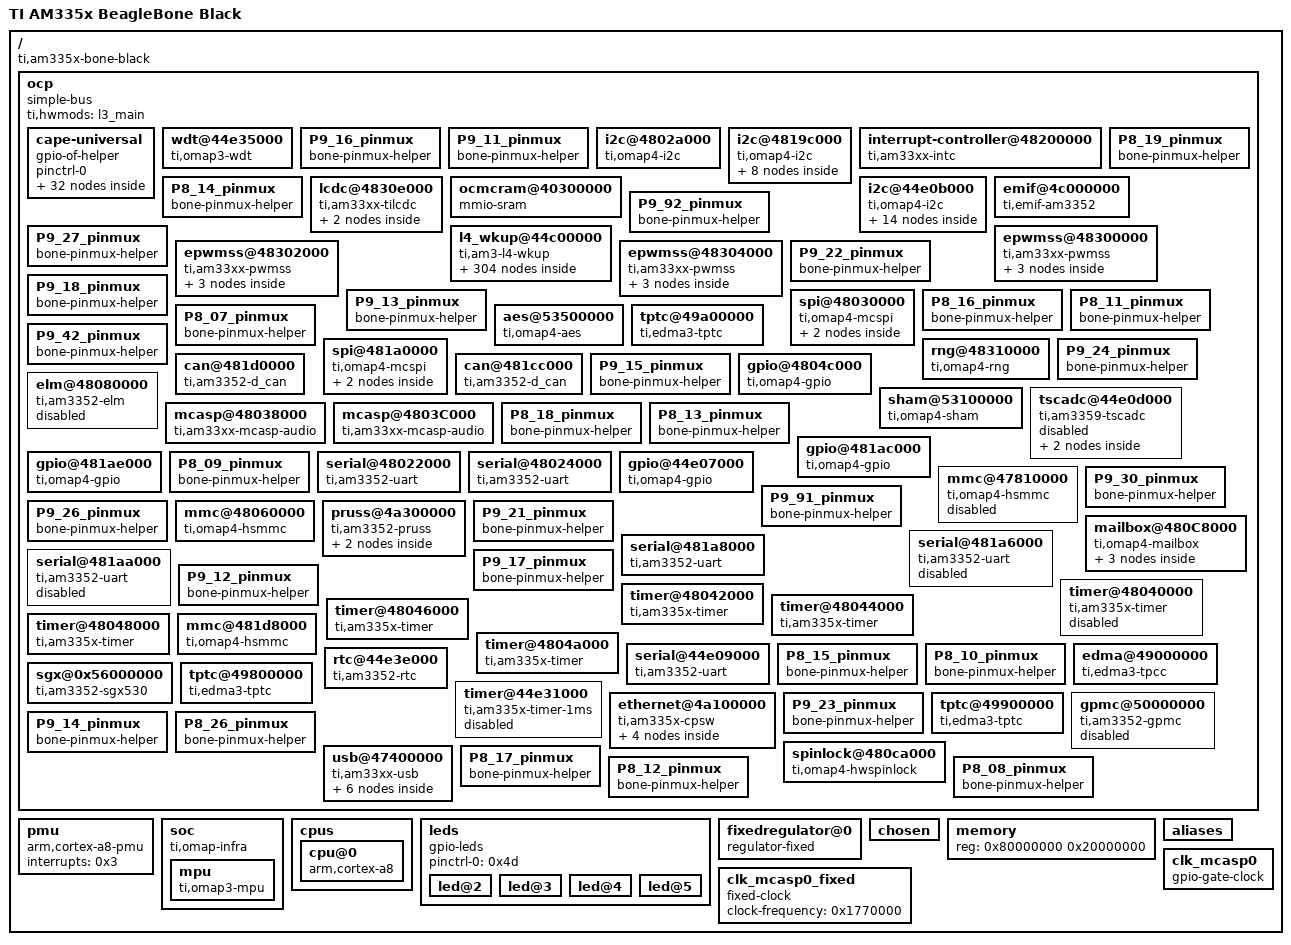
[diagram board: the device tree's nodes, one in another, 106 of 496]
/dts-v1/;

/ {
	model = "TI AM335x BeagleBone Black";
	compatible = "ti,am335x-bone-black", "ti,am335x-bone", "ti,am33xx";
	#address-cells = <0x1>;
	#size-cells = <0x1>;
	interrupt-parent = <0x1>;

	ocp {
		compatible = "simple-bus";
		ranges;
		#address-cells = <0x1>;
		ti,hwmods = "l3_main";
		phandle = <0x58>;
		#size-cells = <0x1>;
		linux,phandle = <0x58>;

		cape-universal {
			pinctrl-0;
			compatible = "gpio-of-helper";
			status = "okay";
			pinctrl-names = "default";

			P8_07 {
				gpio = <0x8f 0x2 0x0>;
				input;
				dir-changeable;
				gpio-name = "P8_07";
			};

			P8_08 {
				gpio = <0x8f 0x3 0x0>;
				input;
				dir-changeable;
				gpio-name = "P8_08";
			};

			P8_09 {
				gpio = <0x8f 0x5 0x0>;
				input;
				dir-changeable;
				gpio-name = "P8_09";
			};

			P8_10 {
				gpio = <0x8f 0x4 0x0>;
				input;
				dir-changeable;
				gpio-name = "P8_10";
			};

			P8_11 {
				gpio = <0x4e 0xd 0x0>;
				input;
				dir-changeable;
				gpio-name = "P8_11";
			};

			P8_12 {
				gpio = <0x4e 0xc 0x0>;
				input;
				dir-changeable;
				gpio-name = "P8_12";
			};

			P8_13 {
				gpio = <0x37 0x17 0x0>;
				input;
				dir-changeable;
				gpio-name = "P8_13";
			};

			P8_14 {
				gpio = <0x37 0x1a 0x0>;
				input;
				dir-changeable;
				gpio-name = "P8_14";
			};

			P8_15 {
				gpio = <0x4e 0xf 0x0>;
				input;
				dir-changeable;
				gpio-name = "P8_15";
			};

			P8_16 {
				gpio = <0x4e 0xe 0x0>;
				input;
				dir-changeable;
				gpio-name = "P8_16";
			};

			P8_17 {
				gpio = <0x37 0x1b 0x0>;
				input;
				dir-changeable;
				gpio-name = "P8_17";
			};

			P8_18 {
				gpio = <0x8f 0x1 0x0>;
				input;
				dir-changeable;
				gpio-name = "P8_18";
			};

			P8_19 {
				gpio = <0x37 0x16 0x0>;
				input;
				dir-changeable;
				gpio-name = "P8_19";
			};

			P8_26 {
				gpio = <0x4e 0x1d 0x0>;
				input;
				dir-changeable;
				gpio-name = "P8_26";
			};

			P9_11 {
				gpio = <0x37 0x1e 0x0>;
				input;
				dir-changeable;
				gpio-name = "P9_11";
			};

			P9_12 {
				gpio = <0x4e 0x1c 0x0>;
				input;
				dir-changeable;
				gpio-name = "P9_12";
			};

			P9_13 {
				gpio = <0x37 0x1f 0x0>;
				input;
				dir-changeable;
				gpio-name = "P9_13";
			};

			P9_14 {
				gpio = <0x4e 0x12 0x0>;
				input;
				dir-changeable;
				gpio-name = "P9_14";
			};

			P9_15 {
				gpio = <0x4e 0x10 0x0>;
				input;
				dir-changeable;
				gpio-name = "P9_15";
			};

			P9_16 {
				gpio = <0x4e 0x13 0x0>;
				input;
				dir-changeable;
				gpio-name = "P9_16";
			};

			P9_17 {
				gpio = <0x37 0x5 0x0>;
				input;
				dir-changeable;
				gpio-name = "P9_17";
			};

			P9_18 {
				gpio = <0x37 0x4 0x0>;
				input;
				dir-changeable;
				gpio-name = "P9_18";
			};

			P9_21 {
				gpio = <0x37 0x3 0x0>;
				input;
				dir-changeable;
				gpio-name = "P9_21";
			};

			P9_22 {
				gpio = <0x37 0x2 0x0>;
				input;
				dir-changeable;
				gpio-name = "P9_22";
			};

			P9_23 {
				gpio = <0x4e 0x11 0x0>;
				input;
				dir-changeable;
				gpio-name = "P9_23";
			};

			P9_24 {
				gpio = <0x37 0xf 0x0>;
				input;
				dir-changeable;
				gpio-name = "P9_24";
			};

			P9_26 {
				gpio = <0x37 0xe 0x0>;
				input;
				dir-changeable;
				gpio-name = "P9_26";
			};

			P9_27 {
				gpio = <0x90 0x13 0x0>;
				input;
				dir-changeable;
				gpio-name = "P9_27";
			};

			P9_30 {
				gpio = <0x90 0x10 0x0>;
				input;
				dir-changeable;
				gpio-name = "P9_30";
			};

			P9_42 {
				gpio = <0x37 0x7 0x0>;
				input;
				dir-changeable;
				gpio-name = "P9_42";
			};

			P9_91 {
				gpio = <0x90 0x14 0x0>;
				input;
				dir-changeable;
				gpio-name = "P9_91";
			};

			P9_92 {
				gpio = <0x90 0x12 0x0>;
				input;
				dir-changeable;
				gpio-name = "P9_92";
			};
		};

		wdt@44e35000 {
			reg = <0x44e35000 0x1000>;
			interrupts = <0x5b>;
			compatible = "ti,omap3-wdt";
			ti,hwmods = "wd_timer2";
			phandle = <0xaa>;
			linux,phandle = <0xaa>;
		};

		P9_16_pinmux {
			pinctrl-0 = <0x13a>;
			pinctrl-1 = <0x13b>;
			pinctrl-2 = <0x13c>;
			pinctrl-3 = <0x13d>;
			pinctrl-4 = <0x13e>;
			compatible = "bone-pinmux-helper";
			status = "okay";
			pinctrl-names = "default", "gpio", "gpio_pu", "gpio_pd", "pwm";
		};

		P9_11_pinmux {
			pinctrl-0 = <0x122>;
			pinctrl-1 = <0x123>;
			pinctrl-2 = <0x124>;
			pinctrl-3 = <0x125>;
			pinctrl-4 = <0x126>;
			compatible = "bone-pinmux-helper";
			status = "okay";
			pinctrl-names = "default", "gpio", "gpio_pu", "gpio_pd", "uart";
		};

		i2c@4802a000 {
			reg = <0x4802a000 0x1000>;
			interrupts = <0x47>;
			pinctrl-0;
			compatible = "ti,omap4-i2c";
			clock-frequency = <0x186a0>;
			status = "okay";
			#address-cells = <0x1>;
			ti,hwmods = "i2c2";
			phandle = <0xa0>;
			#size-cells = <0x0>;
			pinctrl-names = "default";
			linux,phandle = <0xa0>;
		};

		i2c@4819c000 {
			reg = <0x4819c000 0x1000>;
			interrupts = <0x1e>;
			pinctrl-0 = <0x33>;
			compatible = "ti,omap4-i2c";
			clock-frequency = <0x186a0>;
			status = "okay";
			#address-cells = <0x1>;
			ti,hwmods = "i2c3";
			phandle = <0xa1>;
			#size-cells = <0x0>;
			pinctrl-names = "default";
			linux,phandle = <0xa1>;

			cape_eeprom0@54 {
				reg = <0x54>;
				compatible = "at,24c256";
				#address-cells = <0x1>;
				phandle = <0xa2>;
				#size-cells = <0x1>;
				linux,phandle = <0xa2>;

				cape_data@0 {
					reg = <0x0 0x100>;
					phandle = <0x50>;
					linux,phandle = <0x50>;
				};
			};

			cape_eeprom1@55 {
				reg = <0x55>;
				compatible = "at,24c256";
				#address-cells = <0x1>;
				phandle = <0xa3>;
				#size-cells = <0x1>;
				linux,phandle = <0xa3>;

				cape_data@0 {
					reg = <0x0 0x100>;
					phandle = <0x51>;
					linux,phandle = <0x51>;
				};
			};

			cape_eeprom2@56 {
				reg = <0x56>;
				compatible = "at,24c256";
				#address-cells = <0x1>;
				phandle = <0xa4>;
				#size-cells = <0x1>;
				linux,phandle = <0xa4>;

				cape_data@0 {
					reg = <0x0 0x100>;
					phandle = <0x52>;
					linux,phandle = <0x52>;
				};
			};

			cape_eeprom3@57 {
				reg = <0x57>;
				compatible = "at,24c256";
				#address-cells = <0x1>;
				phandle = <0xa5>;
				#size-cells = <0x1>;
				linux,phandle = <0xa5>;

				cape_data@0 {
					reg = <0x0 0x100>;
					phandle = <0x53>;
					linux,phandle = <0x53>;
				};
			};
		};

		interrupt-controller@48200000 {
			reg = <0x48200000 0x1000>;
			compatible = "ti,am33xx-intc";
			#interrupt-cells = <0x1>;
			phandle = <0x1>;
			interrupt-controller;
			linux,phandle = <0x1>;
		};

		P8_19_pinmux {
			pinctrl-0 = <0x119>;
			pinctrl-1 = <0x11a>;
			pinctrl-2 = <0x11b>;
			pinctrl-3 = <0x11c>;
			pinctrl-4 = <0x11d>;
			compatible = "bone-pinmux-helper";
			status = "okay";
			pinctrl-names = "default", "gpio", "gpio_pu", "gpio_pd", "pwm";
		};

		P8_14_pinmux {
			pinctrl-0 = <0xff>;
			pinctrl-1 = <0x100>;
			pinctrl-2 = <0x101>;
			pinctrl-3 = <0x102>;
			pinctrl-4 = <0x103>;
			compatible = "bone-pinmux-helper";
			status = "okay";
			pinctrl-names = "default", "gpio", "gpio_pu", "gpio_pd", "pwm";
		};

		lcdc@4830e000 {
			reg = <0x4830e000 0x1000>;
			interrupts = <0x24>;
			compatible = "ti,am33xx-tilcdc";
			status = "okay";
			ti,hwmods = "lcdc";
			phandle = <0xce>;
			linux,phandle = <0xce>;
			interrupt-parent = <0x1>;

			port {

				endpoint@0 {
					remote-endpoint = <0x4a>;
					phandle = <0x32>;
					linux,phandle = <0x32>;
				};
			};
		};

		ocmcram@40300000 {
			reg = <0x40300000 0x10000>;
			compatible = "mmio-sram";
			map-exec;
			phandle = <0x4>;
			linux,phandle = <0x4>;
		};

		i2c@44e0b000 {
			reg = <0x44e0b000 0x1000>;
			interrupts = <0x46>;
			pinctrl-0 = <0x2f>;
			compatible = "ti,omap4-i2c";
			clock-frequency = <0x61a80>;
			status = "okay";
			#address-cells = <0x1>;
			ti,hwmods = "i2c1";
			phandle = <0x97>;
			#size-cells = <0x0>;
			pinctrl-names = "default";
			linux,phandle = <0x97>;

			baseboard_eeprom@50 {
				reg = <0x50>;
				compatible = "at,24c256";
				#address-cells = <0x1>;
				phandle = <0x9f>;
				#size-cells = <0x1>;
				linux,phandle = <0x9f>;

				baseboard_data@0 {
					reg = <0x0 0x100>;
					phandle = <0x4f>;
					linux,phandle = <0x4f>;
				};
			};

			tps@24 {
				reg = <0x24>;
				interrupts = <0x7>;
				compatible = "ti,tps65217";
				ti,pmic-shutdown-controller;
				phandle = <0x98>;
				linux,phandle = <0x98>;
				interrupt-parent = <0x1>;

				regulators {
					#address-cells = <0x1>;
					#size-cells = <0x0>;

					regulator@0 {
						reg = <0x0>;
						regulator-name = "vdds_dpr";
						regulator-always-on;
						regulator-compatible = "dcdc1";
						phandle = <0x99>;
						linux,phandle = <0x99>;
					};

					regulator@1 {
						reg = <0x1>;
						regulator-name = "vdd_mpu";
						regulator-always-on;
						regulator-min-microvolt = <0xe1d48>;
						regulator-max-microvolt = <0x1506d0>;
						regulator-compatible = "dcdc2";
						phandle = <0x3>;
						regulator-boot-on;
						linux,phandle = <0x3>;
					};

					regulator@2 {
						reg = <0x2>;
						regulator-name = "vdd_core";
						regulator-always-on;
						regulator-min-microvolt = <0xe1d48>;
						regulator-max-microvolt = <0x118c30>;
						regulator-compatible = "dcdc3";
						phandle = <0x9a>;
						regulator-boot-on;
						linux,phandle = <0x9a>;
					};

					regulator@3 {
						reg = <0x3>;
						regulator-name = "vio,vrtc,vdds";
						regulator-always-on;
						regulator-compatible = "ldo1";
						phandle = <0x9b>;
						linux,phandle = <0x9b>;
					};

					regulator@4 {
						reg = <0x4>;
						regulator-name = "vdd_3v3aux";
						regulator-always-on;
						regulator-compatible = "ldo2";
						phandle = <0x9c>;
						linux,phandle = <0x9c>;
					};

					regulator@5 {
						reg = <0x5>;
						regulator-name = "vdd_1v8";
						regulator-always-on;
						regulator-min-microvolt = <0x1b7740>;
						regulator-max-microvolt = <0x1b7740>;
						regulator-compatible = "ldo3";
						phandle = <0x9d>;
						linux,phandle = <0x9d>;
					};

					regulator@6 {
						reg = <0x6>;
						regulator-name = "vdd_3v3a";
						regulator-always-on;
						regulator-compatible = "ldo4";
						phandle = <0x9e>;
						linux,phandle = <0x9e>;
					};
				};
			};

			tda19988 {
				reg = <0x70>;
				pinctrl-0 = <0x30>;
				pinctrl-1 = <0x31>;
				compatible = "nxp,tda998x";
				pinctrl-names = "default", "off";

				port {

					endpoint@0 {
						remote-endpoint = <0x32>;
						phandle = <0x4a>;
						linux,phandle = <0x4a>;
					};
				};
			};
		};

		emif@4c000000 {
			reg = <0x4c000000 0x1000>;
			sram = <0x4>;
			compatible = "ti,emif-am3352";
			phandle = <0x8e>;
			linux,phandle = <0x8e>;
		};

		P9_92_pinmux {
			pinctrl-0 = <0x190>;
			pinctrl-1 = <0x191>;
			pinctrl-2 = <0x192>;
			pinctrl-3 = <0x193>;
			pinctrl-4 = <0x194>;
			pinctrl-5 = <0x195>;
			pinctrl-6 = <0x196>;
			compatible = "bone-pinmux-helper";
			status = "okay";
			pinctrl-names = "default", "gpio", "gpio_pu", "gpio_pd", "qep", "pruout", "pruin";
		};

		P9_27_pinmux {
			pinctrl-0 = <0x172>;
			pinctrl-1 = <0x173>;
			pinctrl-2 = <0x174>;
			pinctrl-3 = <0x175>;
			pinctrl-4 = <0x176>;
			pinctrl-5 = <0x177>;
			pinctrl-6 = <0x178>;
			compatible = "bone-pinmux-helper";
			status = "okay";
			pinctrl-names = "default", "gpio", "gpio_pu", "gpio_pd", "qep", "pruout", "pruin";
		};

		l4_wkup@44c00000 {
			compatible = "ti,am3-l4-wkup", "simple-bus";
			ranges = <0x0 0x44c00000 0x280000>;
			#address-cells = <0x1>;
			phandle = <0x59>;
			#size-cells = <0x1>;
			linux,phandle = <0x59>;

			prcm@200000 {
				reg = <0x200000 0x4000>;
				compatible = "ti,am3-prcm";
				phandle = <0x5a>;
				linux,phandle = <0x5a>;

				clockdomains {
					phandle = <0x7c>;
					linux,phandle = <0x7c>;

					clk_24mhz_clkdm {
						compatible = "ti,clockdomain";
						clocks = <0x12>;
						phandle = <0x7d>;
						linux,phandle = <0x7d>;
					};
				};

				clocks {
					#address-cells = <0x1>;
					phandle = <0x5b>;
					#size-cells = <0x0>;
					linux,phandle = <0x5b>;

					clkdiv32k_ick {
						reg = <0x14c>;
						#clock-cells = <0x0>;
						compatible = "ti,gate-clock";
						ti,bit-shift = <0x1>;
						clocks = <0xe>;
						phandle = <0x12>;
						linux,phandle = <0x12>;
					};

					clkout2_div_ck {
						reg = <0x700>;
						#clock-cells = <0x0>;
						compatible = "ti,divider-clock";
						ti,bit-shift = <0x3>;
						ti,max-div = <0x8>;
						clocks = <0x1b>;
						phandle = <0x20>;
						linux,phandle = <0x20>;
					};

					gpio0_dbclk {
						reg = <0x408>;
						#clock-cells = <0x0>;
						compatible = "ti,gate-clock";
						ti,bit-shift = <0x12>;
						clocks = <0x18>;
						phandle = <0x73>;
						linux,phandle = <0x73>;
					};

					pruss_ocp_gclk {
						reg = <0x530>;
						#clock-cells = <0x0>;
						compatible = "ti,mux-clock";
						clocks = <0x10 0x11>;
						phandle = <0x62>;
						linux,phandle = <0x62>;
					};

					dbg_clka_ck {
						reg = <0x414>;
						#clock-cells = <0x0>;
						compatible = "ti,gate-clock";
						ti,bit-shift = <0x1e>;
						clocks = <0xf>;
						phandle = <0x1d>;
						linux,phandle = <0x1d>;
					};

					gfx_fclk_clksel_ck {
						reg = <0x52c>;
						#clock-cells = <0x0>;
						compatible = "ti,mux-clock";
						ti,bit-shift = <0x1>;
						clocks = <0xf 0xc>;
						phandle = <0x19>;
						linux,phandle = <0x19>;
					};

					l4hs_gclk {
						#clock-cells = <0x0>;
						compatible = "fixed-factor-clock";
						clocks = <0xf>;
						clock-div = <0x1>;
						phandle = <0x6f>;
						clock-mult = <0x1>;
						linux,phandle = <0x6f>;
					};

					dpll_per_m2_ck {
						reg = <0x4ac>;
						#clock-cells = <0x0>;
						compatible = "ti,divider-clock";
						ti,max-div = <0x1f>;
						clocks = <0xb>;
						ti,index-starts-at-one;
						phandle = <0xc>;
						linux,phandle = <0xc>;
					};

					clk_32768_ck {
						#clock-cells = <0x0>;
						compatible = "fixed-clock";
						clock-frequency = <0x8000>;
						phandle = <0x15>;
						linux,phandle = <0x15>;
					};

					virt_24000000_ck {
						#clock-cells = <0x0>;
						compatible = "fixed-clock";
						clock-frequency = <0x16e3600>;
						phandle = <0x23>;
						linux,phandle = <0x23>;
					};

					l3s_gclk {
						#clock-cells = <0x0>;
						compatible = "fixed-factor-clock";
						clocks = <0x16>;
						clock-div = <0x1>;
						phandle = <0x70>;
						clock-mult = <0x1>;
						linux,phandle = <0x70>;
					};

					gpio1_dbclk {
						reg = <0xac>;
						#clock-cells = <0x0>;
						compatible = "ti,gate-clock";
						ti,bit-shift = <0x12>;
						clocks = <0x12>;
						phandle = <0x74>;
						linux,phandle = <0x74>;
					};

					dpll_core_ck {
						reg = <0x490 0x45c 0x468>;
						#clock-cells = <0x0>;
						compatible = "ti,am3-dpll-core-clock";
						clocks = <0x5 0x5>;
						phandle = <0x6>;
						linux,phandle = <0x6>;
					};

					clk_rc32k_ck {
						#clock-cells = <0x0>;
						compatible = "fixed-clock";
						clock-frequency = <0x7d00>;
						phandle = <0x14>;
						linux,phandle = <0x14>;
					};

					trace_pmd_clk_mux_ck {
						reg = <0x414>;
						#clock-cells = <0x0>;
						compatible = "ti,mux-clock";
						ti,bit-shift = <0x14>;
						clocks = <0x1c 0x1d>;
						phandle = <0x1f>;
						linux,phandle = <0x1f>;
					};

					dpll_disp_ck {
						reg = <0x498 0x448 0x454>;
						#clock-cells = <0x0>;
						compatible = "ti,am3-dpll-no-gate-clock";
						clocks = <0x5 0x5>;
						phandle = <0xa>;
						linux,phandle = <0xa>;
					};

					stm_clk_div_ck {
						reg = <0x414>;
						#clock-cells = <0x0>;
						compatible = "ti,divider-clock";
						ti,bit-shift = <0x1b>;
						ti,max-div = <0x40>;
						clocks = <0x1e>;
						ti,index-power-of-two;
						phandle = <0x79>;
						linux,phandle = <0x79>;
					};

					cefuse_fck {
						reg = <0xa20>;
						#clock-cells = <0x0>;
						compatible = "ti,gate-clock";
						ti,bit-shift = <0x1>;
						clocks = <0x5>;
						phandle = <0x61>;
						linux,phandle = <0x61>;
					};

					cpsw_125mhz_gclk {
						#clock-cells = <0x0>;
						compatible = "fixed-factor-clock";
						clocks = <0x17>;
						clock-div = <0x2>;
						phandle = <0x41>;
						clock-mult = <0x1>;
						linux,phandle = <0x41>;
					};

					gpio2_dbclk {
						reg = <0xb0>;
						#clock-cells = <0x0>;
						compatible = "ti,gate-clock";
						ti,bit-shift = <0x12>;
						clocks = <0x12>;
						phandle = <0x75>;
						linux,phandle = <0x75>;
					};

					dpll_core_m4_ck {
						reg = <0x480>;
						#clock-cells = <0x0>;
						compatible = "ti,divider-clock";
						ti,max-div = <0x1f>;
						clocks = <0x7>;
						ti,index-starts-at-one;
						phandle = <0xf>;
						linux,phandle = <0xf>;
					};

					dpll_core_m5_ck {
						reg = <0x484>;
						#clock-cells = <0x0>;
						compatible = "ti,divider-clock";
						ti,max-div = <0x1f>;
						clocks = <0x7>;
						ti,index-starts-at-one;
						phandle = <0x17>;
						linux,phandle = <0x17>;
					};

					dpll_core_m6_ck {
						reg = <0x4d8>;
						#clock-cells = <0x0>;
						compatible = "ti,divider-clock";
						ti,max-div = <0x1f>;
						clocks = <0x7>;
						ti,index-starts-at-one;
						phandle = <0x5c>;
						linux,phandle = <0x5c>;
					};

					virt_25000000_ck {
						#clock-cells = <0x0>;
						compatible = "fixed-clock";
						clock-frequency = <0x17d7840>;
						phandle = <0x24>;
						linux,phandle = <0x24>;
					};

					dpll_core_x2_ck {
						#clock-cells = <0x0>;
						compatible = "ti,am3-dpll-x2-clock";
						clocks = <0x6>;
						phandle = <0x7>;
						linux,phandle = <0x7>;
					};

					dbg_sysclk_ck {
						reg = <0x414>;
						#clock-cells = <0x0>;
						compatible = "ti,gate-clock";
						ti,bit-shift = <0x13>;
						clocks = <0x5>;
						phandle = <0x1c>;
						linux,phandle = <0x1c>;
					};

					clkout2_ck {
						reg = <0x700>;
						#clock-cells = <0x0>;
						compatible = "ti,gate-clock";
						ti,bit-shift = <0x7>;
						clocks = <0x20>;
						phandle = <0x7b>;
						linux,phandle = <0x7b>;
					};

					dpll_disp_m2_ck {
						reg = <0x4a4>;
						#clock-cells = <0x0>;
						compatible = "ti,divider-clock";
						ti,max-div = <0x1f>;
						clocks = <0xa>;
						ti,index-starts-at-one;
						phandle = <0x11>;
						ti,set-rate-parent;
						linux,phandle = <0x11>;
					};

					dpll_mpu_m2_ck {
						reg = <0x4a8>;
						#clock-cells = <0x0>;
						compatible = "ti,divider-clock";
						ti,max-div = <0x1f>;
						clocks = <0x2>;
						ti,index-starts-at-one;
						phandle = <0x5d>;
						linux,phandle = <0x5d>;
					};

					sysclk_div_ck {
						#clock-cells = <0x0>;
						compatible = "fixed-factor-clock";
						clocks = <0xf>;
						clock-div = <0x1>;
						phandle = <0x72>;
						clock-mult = <0x1>;
						linux,phandle = <0x72>;
					};

					mmc_clk {
						#clock-cells = <0x0>;
						compatible = "fixed-factor-clock";
						clocks = <0xc>;
						clock-div = <0x2>;
						phandle = <0x77>;
						clock-mult = <0x1>;
						linux,phandle = <0x77>;
					};

					clkdiv32k_ck {
						#clock-cells = <0x0>;
						compatible = "fixed-factor-clock";
						clocks = <0xd>;
						clock-div = <0x2dc>;
						phandle = <0xe>;
						clock-mult = <0x1>;
						linux,phandle = <0xe>;
					};

					ieee5000_fck {
						reg = <0xe4>;
						#clock-cells = <0x0>;
						compatible = "ti,gate-clock";
						ti,bit-shift = <0x1>;
						clocks = <0x16>;
						phandle = <0x6c>;
						linux,phandle = <0x6c>;
					};

					cpsw_cpts_rft_clk {
						reg = <0x520>;
						#clock-cells = <0x0>;
						compatible = "ti,mux-clock";
						clocks = <0x17 0xf>;
						phandle = <0x42>;
						linux,phandle = <0x42>;
					};

					mmu_fck {
						reg = <0x914>;
						#clock-cells = <0x0>;
						compatible = "ti,gate-clock";
						ti,bit-shift = <0x1>;
						clocks = <0xf>;
						phandle = <0x63>;
						linux,phandle = <0x63>;
					};

					gpio3_dbclk {
						reg = <0xb4>;
						#clock-cells = <0x0>;
						compatible = "ti,gate-clock";
						ti,bit-shift = <0x12>;
						clocks = <0x12>;
						phandle = <0x76>;
						linux,phandle = <0x76>;
					};

					stm_pmd_clock_mux_ck {
						reg = <0x414>;
						#clock-cells = <0x0>;
						compatible = "ti,mux-clock";
						ti,bit-shift = <0x16>;
						clocks = <0x1c 0x1d>;
						phandle = <0x1e>;
						linux,phandle = <0x1e>;
					};

					gfx_fck_div_ck {
						reg = <0x52c>;
						#clock-cells = <0x0>;
						compatible = "ti,divider-clock";
						ti,max-div = <0x2>;
						clocks = <0x19>;
						phandle = <0x78>;
						linux,phandle = <0x78>;
					};

					l3_gclk {
						#clock-cells = <0x0>;
						compatible = "fixed-factor-clock";
						clocks = <0xf>;
						clock-div = <0x1>;
						phandle = <0x10>;
						clock-mult = <0x1>;
						linux,phandle = <0x10>;
					};

					l4_rtc_gclk {
						#clock-cells = <0x0>;
						compatible = "fixed-factor-clock";
						clocks = <0xf>;
						clock-div = <0x2>;
						phandle = <0x6e>;
						clock-mult = <0x1>;
						linux,phandle = <0x6e>;
					};

					dpll_per_m2_div4_wkupdm_ck {
						#clock-cells = <0x0>;
						compatible = "fixed-factor-clock";
						clocks = <0xc>;
						clock-div = <0x4>;
						phandle = <0x5f>;
						clock-mult = <0x1>;
						linux,phandle = <0x5f>;
					};

					tclkin_ck {
						#clock-cells = <0x0>;
						compatible = "fixed-clock";
						clock-frequency = <0xb71b00>;
						phandle = <0x13>;
						linux,phandle = <0x13>;
					};

					dpll_ddr_m2_ck {
						reg = <0x4a0>;
						#clock-cells = <0x0>;
						compatible = "ti,divider-clock";
						ti,max-div = <0x1f>;
						clocks = <0x8>;
						ti,index-starts-at-one;
						phandle = <0x9>;
						linux,phandle = <0x9>;
					};

					sysclkout_pre_ck {
						reg = <0x700>;
						#clock-cells = <0x0>;
						compatible = "ti,mux-clock";
						clocks = <0x15 0x10 0x9 0xc 0x1a>;
						phandle = <0x1b>;
						linux,phandle = <0x1b>;
					};

					virt_26000000_ck {
						#clock-cells = <0x0>;
						compatible = "fixed-clock";
						clock-frequency = <0x18cba80>;
						phandle = <0x25>;
						linux,phandle = <0x25>;
					};

					dpll_per_m2_div4_ck {
						#clock-cells = <0x0>;
						compatible = "fixed-factor-clock";
						clocks = <0xc>;
						clock-div = <0x4>;
						phandle = <0x60>;
						clock-mult = <0x1>;
						linux,phandle = <0x60>;
					};

					timer1_fck {
						reg = <0x528>;
						#clock-cells = <0x0>;
						compatible = "ti,mux-clock";
						clocks = <0x5 0x12 0x13 0x14 0x15>;
						phandle = <0x64>;
						linux,phandle = <0x64>;
					};

					timer2_fck {
						reg = <0x508>;
						#clock-cells = <0x0>;
						compatible = "ti,mux-clock";
						clocks = <0x13 0x5 0x12>;
						phandle = <0x65>;
						linux,phandle = <0x65>;
					};

					timer3_fck {
						reg = <0x50c>;
						#clock-cells = <0x0>;
						compatible = "ti,mux-clock";
						clocks = <0x13 0x5 0x12>;
						phandle = <0x66>;
						linux,phandle = <0x66>;
					};

					usbotg_fck {
						reg = <0x47c>;
						#clock-cells = <0x0>;
						compatible = "ti,gate-clock";
						ti,bit-shift = <0x8>;
						clocks = <0xb>;
						phandle = <0x6b>;
						linux,phandle = <0x6b>;
					};

					timer4_fck {
						reg = <0x510>;
						#clock-cells = <0x0>;
						compatible = "ti,mux-clock";
						clocks = <0x13 0x5 0x12>;
						phandle = <0x67>;
						linux,phandle = <0x67>;
					};

					timer5_fck {
						reg = <0x518>;
						#clock-cells = <0x0>;
						compatible = "ti,mux-clock";
						clocks = <0x13 0x5 0x12>;
						phandle = <0x68>;
						linux,phandle = <0x68>;
					};

					timer6_fck {
						reg = <0x51c>;
						#clock-cells = <0x0>;
						compatible = "ti,mux-clock";
						clocks = <0x13 0x5 0x12>;
						phandle = <0x69>;
						linux,phandle = <0x69>;
					};

					timer7_fck {
						reg = <0x504>;
						#clock-cells = <0x0>;
						compatible = "ti,mux-clock";
						clocks = <0x13 0x5 0x12>;
						phandle = <0x6a>;
						linux,phandle = <0x6a>;
					};

					dpll_ddr_ck {
						reg = <0x494 0x434 0x440>;
						#clock-cells = <0x0>;
						compatible = "ti,am3-dpll-no-gate-clock";
						clocks = <0x5 0x5>;
						phandle = <0x8>;
						linux,phandle = <0x8>;
					};

					gpio0_dbclk_mux_ck {
						reg = <0x53c>;
						#clock-cells = <0x0>;
						compatible = "ti,mux-clock";
						clocks = <0x14 0x15 0x12>;
						phandle = <0x18>;
						linux,phandle = <0x18>;
					};

					l4ls_gclk {
						#clock-cells = <0x0>;
						compatible = "fixed-factor-clock";
						clocks = <0x16>;
						clock-div = <0x1>;
						phandle = <0x26>;
						clock-mult = <0x1>;
						linux,phandle = <0x26>;
					};

					dpll_ddr_m2_div2_ck {
						#clock-cells = <0x0>;
						compatible = "fixed-factor-clock";
						clocks = <0x9>;
						clock-div = <0x2>;
						phandle = <0x5e>;
						clock-mult = <0x1>;
						linux,phandle = <0x5e>;
					};

					trace_clk_div_ck {
						reg = <0x414>;
						#clock-cells = <0x0>;
						compatible = "ti,divider-clock";
						ti,bit-shift = <0x18>;
						ti,max-div = <0x40>;
						clocks = <0x1f>;
						ti,index-power-of-two;
						phandle = <0x7a>;
						linux,phandle = <0x7a>;
					};

					virt_19200000_ck {
						#clock-cells = <0x0>;
						compatible = "fixed-clock";
						clock-frequency = <0x124f800>;
						phandle = <0x22>;
						linux,phandle = <0x22>;
					};

					dpll_mpu_ck {
						reg = <0x488 0x420 0x42c>;
						#clock-cells = <0x0>;
						compatible = "ti,am3-dpll-clock";
						clocks = <0x5 0x5>;
						phandle = <0x2>;
						linux,phandle = <0x2>;
					};

					dpll_per_ck {
						reg = <0x48c 0x470 0x49c>;
						#clock-cells = <0x0>;
						compatible = "ti,am3-dpll-no-gate-j-type-clock";
						clocks = <0x5 0x5>;
						phandle = <0xb>;
						linux,phandle = <0xb>;
					};

					clk_24mhz {
						#clock-cells = <0x0>;
						compatible = "fixed-factor-clock";
						clocks = <0xc>;
						clock-div = <0x8>;
						phandle = <0xd>;
						clock-mult = <0x1>;
						linux,phandle = <0xd>;
					};

					dpll_core_m4_div2_ck {
						#clock-cells = <0x0>;
						compatible = "fixed-factor-clock";
						clocks = <0xf>;
						clock-div = <0x2>;
						phandle = <0x16>;
						clock-mult = <0x1>;
						linux,phandle = <0x16>;
					};

					l4fw_gclk {
						#clock-cells = <0x0>;
						compatible = "fixed-factor-clock";
						clocks = <0x16>;
						clock-div = <0x1>;
						phandle = <0x71>;
						clock-mult = <0x1>;
						linux,phandle = <0x71>;
					};

					wdt1_fck {
						reg = <0x538>;
						#clock-cells = <0x0>;
						compatible = "ti,mux-clock";
						clocks = <0x14 0x12>;
						phandle = <0x6d>;
						linux,phandle = <0x6d>;
					};

					lcd_gclk {
						reg = <0x534>;
						#clock-cells = <0x0>;
						compatible = "ti,mux-clock";
						clocks = <0x11 0x17 0xc>;
						phandle = <0x1a>;
						ti,set-rate-parent;
						linux,phandle = <0x1a>;
					};
				};
			};

			wkup_m3@100000 {
				reg = <0x100000 0x4000 0x180000 0x2000>;
				reg-names = "umem", "dmem";
				compatible = "ti,am3352-wkup-m3";
				ti,pm-firmware = "am335x-pm-firmware.elf";
				ti,hwmods = "wkup_m3";
				phandle = <0x27>;
				linux,phandle = <0x27>;
			};

			scm@210000 {
				reg = <0x210000 0x2000>;
				compatible = "ti,am3-scm", "simple-bus";
				ranges = <0x0 0x210000 0x2000>;
				#address-cells = <0x1>;
				phandle = <0x7e>;
				#size-cells = <0x1>;
				linux,phandle = <0x7e>;

				clockdomains {
					phandle = <0x8d>;
					linux,phandle = <0x8d>;
				};

				pinmux@800 {
					reg = <0x800 0x238>;
					pinctrl-0 = <0x21>;
					compatible = "pinctrl-single";
					#address-cells = <0x1>;
					phandle = <0x7f>;
					#size-cells = <0x0>;
					pinctrl-names = "default";
					linux,phandle = <0x7f>;
					pinctrl-single,function-mask = <0x7f>;
					pinctrl-single,register-width = <0x20>;

					pinmux_P8_16_qep_pin {
						pinctrl-single,pins = <0x38 0x24>;
						phandle = <0x10f>;
						linux,phandle = <0x10f>;
					};

					pinmux_P9_42_gpio_pin {
						pinctrl-single,pins = <0x164 0x2f>;
						phandle = <0x189>;
						linux,phandle = <0x189>;
					};

					pinmux_P9_24_gpio_pin {
						pinctrl-single,pins = <0x184 0x2f>;
						phandle = <0x163>;
						linux,phandle = <0x163>;
					};

					pinmux_P8_18_gpio_pin {
						pinctrl-single,pins = <0x8c 0x2f>;
						phandle = <0x116>;
						linux,phandle = <0x116>;
					};

					pinmux_P9_17_gpio_pin {
						pinctrl-single,pins = <0x15c 0x2f>;
						phandle = <0x140>;
						linux,phandle = <0x140>;
					};

					pinmux_P9_42_spics_pin {
						pinctrl-single,pins = <0x164 0x22>;
						phandle = <0x18e>;
						linux,phandle = <0x18e>;
					};

					pinmux_P8_14_gpio_pin {
						pinctrl-single,pins = <0x28 0x2f>;
						phandle = <0x100>;
						linux,phandle = <0x100>;
					};

					pinmux_P9_13_gpio_pin {
						pinctrl-single,pins = <0x74 0x2f>;
						phandle = <0x12c>;
						linux,phandle = <0x12c>;
					};

					pinmux_P8_10_gpio_pin {
						pinctrl-single,pins = <0x98 0x2f>;
						phandle = <0xea>;
						linux,phandle = <0xea>;
					};

					pinmux_P8_07_gpio_pin {
						pinctrl-single,pins = <0x90 0x2f>;
						phandle = <0xdb>;
						linux,phandle = <0xdb>;
					};

					pinmux_P8_11_pruout_pin {
						pinctrl-single,pins = <0x34 0x26>;
						phandle = <0xf2>;
						linux,phandle = <0xf2>;
					};

					pinmux_P9_14_pwm_pin {
						pinctrl-single,pins = <0x48 0x26>;
						phandle = <0x134>;
						linux,phandle = <0x134>;
					};

					pinmux_P9_26_pruin_pin {
						pinctrl-single,pins = <0x180 0x36>;
						phandle = <0x171>;
						linux,phandle = <0x171>;
					};

					pinmux_P8_17_gpio_pd_pin {
						pinctrl-single,pins = <0x2c 0x27>;
						phandle = <0x113>;
						linux,phandle = <0x113>;
					};

					pinmux_P9_21_gpio_pd_pin {
						pinctrl-single,pins = <0x154 0x27>;
						phandle = <0x150>;
						linux,phandle = <0x150>;
					};

					pinmux_P8_13_gpio_pd_pin {
						pinctrl-single,pins = <0x24 0x27>;
						phandle = <0xfd>;
						linux,phandle = <0xfd>;
					};

					pinmux_P9_18_gpio_pd_pin {
						pinctrl-single,pins = <0x158 0x27>;
						phandle = <0x149>;
						linux,phandle = <0x149>;
					};

					pinmux_P9_14_gpio_pd_pin {
						pinctrl-single,pins = <0x48 0x27>;
						phandle = <0x133>;
						linux,phandle = <0x133>;
					};

					pinmux_P8_17_gpio_pu_pin {
						pinctrl-single,pins = <0x2c 0x37>;
						phandle = <0x112>;
						linux,phandle = <0x112>;
					};

					pinmux_P9_17_spi_pin {
						pinctrl-single,pins = <0x15c 0x30>;
						phandle = <0x143>;
						linux,phandle = <0x143>;
					};

					pinmux_P9_21_gpio_pu_pin {
						pinctrl-single,pins = <0x154 0x37>;
						phandle = <0x14f>;
						linux,phandle = <0x14f>;
					};

					pinmux_P8_13_gpio_pu_pin {
						pinctrl-single,pins = <0x24 0x37>;
						phandle = <0xfc>;
						linux,phandle = <0xfc>;
					};

					pinmux_P9_18_gpio_pu_pin {
						pinctrl-single,pins = <0x158 0x37>;
						phandle = <0x148>;
						linux,phandle = <0x148>;
					};

					pinmux_P9_14_gpio_pu_pin {
						pinctrl-single,pins = <0x48 0x37>;
						phandle = <0x132>;
						linux,phandle = <0x132>;
					};

					pinmux_P9_24_can_pin {
						pinctrl-single,pins = <0x184 0x32>;
						phandle = <0x167>;
						linux,phandle = <0x167>;
					};

					pinmux_P9_27_pruout_pin {
						pinctrl-single,pins = <0x1a4 0x25>;
						phandle = <0x177>;
						linux,phandle = <0x177>;
					};

					pinmux_P8_11_qep_pin {
						pinctrl-single,pins = <0x34 0x24>;
						phandle = <0xf3>;
						linux,phandle = <0xf3>;
					};

					pinmux_P8_08_timer_pin {
						pinctrl-single,pins = <0x94 0x32>;
						phandle = <0xe3>;
						linux,phandle = <0xe3>;
					};

					pinmux_P8_17_default_pin {
						pinctrl-single,pins = <0x2c 0x27>;
						phandle = <0x110>;
						linux,phandle = <0x110>;
					};

					pinmux_P8_12_pruout_pin {
						pinctrl-single,pins = <0x30 0x26>;
						phandle = <0xf8>;
						linux,phandle = <0xf8>;
					};

					pinmux_P9_21_default_pin {
						pinctrl-single,pins = <0x154 0x37>;
						phandle = <0x14d>;
						linux,phandle = <0x14d>;
					};

					pinmux_P8_13_default_pin {
						pinctrl-single,pins = <0x24 0x27>;
						phandle = <0xfa>;
						linux,phandle = <0xfa>;
					};

					pinmux_P9_18_default_pin {
						pinctrl-single,pins = <0x158 0x37>;
						phandle = <0x146>;
						linux,phandle = <0x146>;
					};

					pinmux_P9_22_pwm_pin {
						pinctrl-single,pins = <0x150 0x33>;
						phandle = <0x15c>;
						linux,phandle = <0x15c>;
					};

					pinmux_P9_14_default_pin {
						pinctrl-single,pins = <0x48 0x27>;
						phandle = <0x130>;
						linux,phandle = <0x130>;
					};

					pinmux_P9_91_pruin_pin {
						pinctrl-single,pins = <0x1a8 0x26>;
						phandle = <0x187>;
						linux,phandle = <0x187>;
					};

					pinmux_P9_16_pwm_pin {
						pinctrl-single,pins = <0x4c 0x26>;
						phandle = <0x13e>;
						linux,phandle = <0x13e>;
					};

					pinmux_P9_41_timer_pin {
						pinctrl-single,pins = <0x1b4 0x24>;
						phandle = <0x19b>;
						linux,phandle = <0x19b>;
					};

					pinmux_P9_91_pruout_pin {
						pinctrl-single,pins = <0x1a8 0x25>;
						phandle = <0x186>;
						linux,phandle = <0x186>;
					};

					pinmux_P9_22_i2c_pin {
						pinctrl-single,pins = <0x150 0x32>;
						phandle = <0x15b>;
						linux,phandle = <0x15b>;
					};

					pinmux_P8_16_pruin_pin {
						pinctrl-single,pins = <0x38 0x26>;
						phandle = <0x10e>;
						linux,phandle = <0x10e>;
					};

					pinmux_emmc_pins {
						pinctrl-single,pins = <0x80 0x32 0x84 0x32 0x0 0x31 0x4 0x31 0x8 0x31 0xc 0x31 0x10 0x31 0x14 0x31 0x18 0x31 0x1c 0x31>;
						phandle = <0x39>;
						linux,phandle = <0x39>;
					};

					cpsw_default {
						pinctrl-single,pins = <0x108 0x28 0x10c 0x28 0x110 0x30 0x114 0x0 0x118 0x30 0x11c 0x0 0x120 0x0 0x124 0x0 0x128 0x0 0x12c 0x30 0x130 0x30 0x134 0x30 0x138 0x30 0x13c 0x30 0x140 0x30>;
						phandle = <0x43>;
						linux,phandle = <0x43>;
					};

					pinmux_P9_91_qep_pin {
						pinctrl-single,pins = <0x1a8 0x21>;
						phandle = <0x185>;
						linux,phandle = <0x185>;
					};

					pinmux_P9_26_can_pin {
						pinctrl-single,pins = <0x180 0x32>;
						phandle = <0x16f>;
						linux,phandle = <0x16f>;
					};

					pinmux_P9_91_gpio_pd_pin {
						pinctrl-single,pins = <0x1a8 0x27>;
						phandle = <0x184>;
						linux,phandle = <0x184>;
					};

					pinmux_P8_26_gpio_pin {
						pinctrl-single,pins = <0x7c 0x2f>;
						phandle = <0x11f>;
						linux,phandle = <0x11f>;
					};

					pinmux_P9_21_gpio_pin {
						pinctrl-single,pins = <0x154 0x2f>;
						phandle = <0x14e>;
						linux,phandle = <0x14e>;
					};

					pinmux_P9_30_pwm_pin {
						pinctrl-single,pins = <0x198 0x21>;
						phandle = <0x17d>;
						linux,phandle = <0x17d>;
					};

					pinmux_P8_19_gpio_pin {
						pinctrl-single,pins = <0x20 0x2f>;
						phandle = <0x11a>;
						linux,phandle = <0x11a>;
					};

					pinmux_P9_18_gpio_pin {
						pinctrl-single,pins = <0x158 0x2f>;
						phandle = <0x147>;
						linux,phandle = <0x147>;
					};

					pinmux_P8_15_gpio_pin {
						pinctrl-single,pins = <0x3c 0x2f>;
						phandle = <0x105>;
						linux,phandle = <0x105>;
					};

					pinmux_P9_14_gpio_pin {
						pinctrl-single,pins = <0x48 0x2f>;
						phandle = <0x131>;
						linux,phandle = <0x131>;
					};

					pinmux_P9_91_gpio_pu_pin {
						pinctrl-single,pins = <0x1a8 0x37>;
						phandle = <0x183>;
						linux,phandle = <0x183>;
					};

					pinmux_P8_11_gpio_pin {
						pinctrl-single,pins = <0x34 0x2f>;
						phandle = <0xef>;
						linux,phandle = <0xef>;
					};

					pinmux_P8_08_gpio_pin {
						pinctrl-single,pins = <0x94 0x2f>;
						phandle = <0xe0>;
						linux,phandle = <0xe0>;
					};

					pinmux_P9_92_pruout_pin {
						pinctrl-single,pins = <0x1a0 0x25>;
						phandle = <0x195>;
						linux,phandle = <0x195>;
					};

					pinmux_P9_26_gpio_pd_pin {
						pinctrl-single,pins = <0x180 0x27>;
						phandle = <0x16d>;
						linux,phandle = <0x16d>;
					};

					pinmux_P8_18_gpio_pd_pin {
						pinctrl-single,pins = <0x8c 0x27>;
						phandle = <0x118>;
						linux,phandle = <0x118>;
					};

					pinmux_P9_18_pwm_pin {
						pinctrl-single,pins = <0x158 0x33>;
						phandle = <0x14c>;
						linux,phandle = <0x14c>;
					};

					pinmux_P9_22_gpio_pd_pin {
						pinctrl-single,pins = <0x150 0x27>;
						phandle = <0x158>;
						linux,phandle = <0x158>;
					};

					pinmux_P8_14_gpio_pd_pin {
						pinctrl-single,pins = <0x28 0x27>;
						phandle = <0x102>;
						linux,phandle = <0x102>;
					};

					pinmux_P8_10_gpio_pd_pin {
						pinctrl-single,pins = <0x98 0x27>;
						phandle = <0xec>;
						linux,phandle = <0xec>;
					};

					pinmux_P9_15_gpio_pd_pin {
						pinctrl-single,pins = <0x40 0x27>;
						phandle = <0x138>;
						linux,phandle = <0x138>;
					};

					pinmux_P8_07_gpio_pd_pin {
						pinctrl-single,pins = <0x90 0x27>;
						phandle = <0xdd>;
						linux,phandle = <0xdd>;
					};

					nxp_hdmi_bonelt_off_pins {
						pinctrl-single,pins = <0x1b0 0x3>;
						phandle = <0x31>;
						linux,phandle = <0x31>;
					};

					pinmux_P9_11_gpio_pd_pin {
						pinctrl-single,pins = <0x70 0x27>;
						phandle = <0x125>;
						linux,phandle = <0x125>;
					};

					pinmux_P9_26_gpio_pu_pin {
						pinctrl-single,pins = <0x180 0x37>;
						phandle = <0x16c>;
						linux,phandle = <0x16c>;
					};

					pinmux_P8_18_gpio_pu_pin {
						pinctrl-single,pins = <0x8c 0x37>;
						phandle = <0x117>;
						linux,phandle = <0x117>;
					};

					pinmux_P9_22_gpio_pu_pin {
						pinctrl-single,pins = <0x150 0x37>;
						phandle = <0x157>;
						linux,phandle = <0x157>;
					};

					pinmux_P8_14_gpio_pu_pin {
						pinctrl-single,pins = <0x28 0x37>;
						phandle = <0x101>;
						linux,phandle = <0x101>;
					};

					pinmux_P8_10_gpio_pu_pin {
						pinctrl-single,pins = <0x98 0x37>;
						phandle = <0xeb>;
						linux,phandle = <0xeb>;
					};

					pinmux_P9_24_i2c_pin {
						pinctrl-single,pins = <0x184 0x33>;
						phandle = <0x168>;
						linux,phandle = <0x168>;
					};

					pinmux_P9_15_gpio_pu_pin {
						pinctrl-single,pins = <0x40 0x37>;
						phandle = <0x137>;
						linux,phandle = <0x137>;
					};

					pinmux_P8_07_gpio_pu_pin {
						pinctrl-single,pins = <0x90 0x37>;
						phandle = <0xdc>;
						linux,phandle = <0xdc>;
					};

					pinmux_P9_91_default_pin {
						pinctrl-single,pins = <0x1a8 0x27>;
						phandle = <0x181>;
						linux,phandle = <0x181>;
					};

					pinmux_P9_11_gpio_pu_pin {
						pinctrl-single,pins = <0x70 0x37>;
						phandle = <0x124>;
						linux,phandle = <0x124>;
					};

					pinmux_P8_13_pwm_pin {
						pinctrl-single,pins = <0x24 0x24>;
						phandle = <0xfe>;
						linux,phandle = <0xfe>;
					};

					pinmux_P8_10_timer_pin {
						pinctrl-single,pins = <0x98 0x32>;
						phandle = <0xed>;
						linux,phandle = <0xed>;
					};

					pinmux_P9_18_i2c_pin {
						pinctrl-single,pins = <0x158 0x32>;
						phandle = <0x14b>;
						linux,phandle = <0x14b>;
					};

					pinmux_P9_42_uart_pin {
						pinctrl-single,pins = <0x164 0x21>;
						phandle = <0x18d>;
						linux,phandle = <0x18d>;
					};

					pinmux_P9_26_default_pin {
						pinctrl-single,pins = <0x180 0x37>;
						phandle = <0x16a>;
						linux,phandle = <0x16a>;
					};

					pinmux_P8_18_default_pin {
						pinctrl-single,pins = <0x8c 0x27>;
						phandle = <0x115>;
						linux,phandle = <0x115>;
					};

					pinmux_P9_22_default_pin {
						pinctrl-single,pins = <0x150 0x37>;
						phandle = <0x155>;
						linux,phandle = <0x155>;
					};

					pinmux_P8_14_default_pin {
						pinctrl-single,pins = <0x28 0x27>;
						phandle = <0xff>;
						linux,phandle = <0xff>;
					};

					pinmux_P8_10_default_pin {
						pinctrl-single,pins = <0x98 0x37>;
						phandle = <0xe9>;
						linux,phandle = <0xe9>;
					};

					pinmux_P9_15_default_pin {
						pinctrl-single,pins = <0x40 0x27>;
						phandle = <0x135>;
						linux,phandle = <0x135>;
					};

					pinmux_P8_15_qep_pin {
						pinctrl-single,pins = <0x3c 0x24>;
						phandle = <0x109>;
						linux,phandle = <0x109>;
					};

					pinmux_P8_07_default_pin {
						pinctrl-single,pins = <0x90 0x37>;
						phandle = <0xda>;
						linux,phandle = <0xda>;
					};

					pinmux_P9_11_default_pin {
						pinctrl-single,pins = <0x70 0x37>;
						phandle = <0x122>;
						linux,phandle = <0x122>;
					};

					pinmux_P8_07_timer_pin {
						pinctrl-single,pins = <0x90 0x32>;
						phandle = <0xde>;
						linux,phandle = <0xde>;
					};

					pinmux_P9_24_uart_pin {
						pinctrl-single,pins = <0x184 0x30>;
						phandle = <0x166>;
						linux,phandle = <0x166>;
					};

					nxp_hdmi_bonelt_pins {
						pinctrl-single,pins = <0x1b0 0x3 0xa0 0x8 0xa4 0x8 0xa8 0x8 0xac 0x8 0xb0 0x8 0xb4 0x8 0xb8 0x8 0xbc 0x8 0xc0 0x8 0xc4 0x8 0xc8 0x8 0xcc 0x8 0xd0 0x8 0xd4 0x8 0xd8 0x8 0xdc 0x8 0xe0 0x0 0xe4 0x0 0xe8 0x0 0xec 0x0>;
						phandle = <0x30>;
						linux,phandle = <0x30>;
					};

					pinmux_P9_13_uart_pin {
						pinctrl-single,pins = <0x74 0x36>;
						phandle = <0x12f>;
						linux,phandle = <0x12f>;
					};

					pinmux_P9_91_gpio_pin {
						pinctrl-single,pins = <0x1a8 0x2f>;
						phandle = <0x182>;
						linux,phandle = <0x182>;
					};

					pinmux_P8_15_pruin_pin {
						pinctrl-single,pins = <0x3c 0x26>;
						phandle = <0x108>;
						linux,phandle = <0x108>;
					};

					pinmux_P9_26_i2c_pin {
						pinctrl-single,pins = <0x180 0x33>;
						phandle = <0x170>;
						linux,phandle = <0x170>;
					};

					pinmux_P9_22_spi_pin {
						pinctrl-single,pins = <0x150 0x30>;
						phandle = <0x159>;
						linux,phandle = <0x159>;
					};

					cpsw_sleep {
						pinctrl-single,pins = <0x108 0x27 0x10c 0x27 0x110 0x27 0x114 0x27 0x118 0x27 0x11c 0x27 0x120 0x27 0x124 0x27 0x128 0x27 0x12c 0x27 0x130 0x27 0x134 0x27 0x138 0x27 0x13c 0x27 0x140 0x27>;
						phandle = <0x44>;
						linux,phandle = <0x44>;
					};

					pinmux_P9_92_gpio_pd_pin {
						pinctrl-single,pins = <0x1a0 0x27>;
						phandle = <0x193>;
						linux,phandle = <0x193>;
					};

					pinmux_P9_26_gpio_pin {
						pinctrl-single,pins = <0x180 0x2f>;
						phandle = <0x16b>;
						linux,phandle = <0x16b>;
					};

					pinmux_P9_22_gpio_pin {
						pinctrl-single,pins = <0x150 0x2f>;
						phandle = <0x156>;
						linux,phandle = <0x156>;
					};

					pinmux_P8_16_gpio_pin {
						pinctrl-single,pins = <0x38 0x2f>;
						phandle = <0x10b>;
						linux,phandle = <0x10b>;
					};

					pinmux_P9_15_gpio_pin {
						pinctrl-single,pins = <0x40 0x2f>;
						phandle = <0x136>;
						linux,phandle = <0x136>;
					};

					pinmux_P9_92_gpio_pu_pin {
						pinctrl-single,pins = <0x1a0 0x37>;
						phandle = <0x192>;
						linux,phandle = <0x192>;
					};

					pinmux_P8_12_gpio_pin {
						pinctrl-single,pins = <0x30 0x2f>;
						phandle = <0xf5>;
						linux,phandle = <0xf5>;
					};

					pinmux_P9_11_gpio_pin {
						pinctrl-single,pins = <0x70 0x2f>;
						phandle = <0x123>;
						linux,phandle = <0x123>;
					};

					pinmux_P9_42_spiclk_pin {
						pinctrl-single,pins = <0x164 0x24>;
						phandle = <0x18f>;
						linux,phandle = <0x18f>;
					};

					pinmux_P8_09_gpio_pin {
						pinctrl-single,pins = <0x9c 0x2f>;
						phandle = <0xe5>;
						linux,phandle = <0xe5>;
					};

					pinmux_clkout2_pin {
						pinctrl-single,pins = <0x1b4 0x3>;
						phandle = <0x21>;
						linux,phandle = <0x21>;
					};

					pinmux_P9_41_gpio_pd_pin {
						pinctrl-single,pins = <0x1b4 0x27>;
						phandle = <0x19a>;
						linux,phandle = <0x19a>;
					};

					pinmux_mmc1_pins_sleep {
						pinctrl-single,pins = <0xf0 0x27 0xf4 0x27 0xf8 0x27 0xfc 0x27 0x100 0x27 0x104 0x27 0x160 0x27>;
						phandle = <0x36>;
						linux,phandle = <0x36>;
					};

					pinmux_P8_26_gpio_pd_pin {
						pinctrl-single,pins = <0x7c 0x27>;
						phandle = <0x121>;
						linux,phandle = <0x121>;
					};

					pinmux_P9_30_gpio_pd_pin {
						pinctrl-single,pins = <0x198 0x27>;
						phandle = <0x17c>;
						linux,phandle = <0x17c>;
					};

					pinmux_P9_27_gpio_pd_pin {
						pinctrl-single,pins = <0x1a4 0x27>;
						phandle = <0x175>;
						linux,phandle = <0x175>;
					};

					pinmux_P8_19_gpio_pd_pin {
						pinctrl-single,pins = <0x20 0x27>;
						phandle = <0x11c>;
						linux,phandle = <0x11c>;
					};

					pinmux_P9_23_gpio_pd_pin {
						pinctrl-single,pins = <0x44 0x27>;
						phandle = <0x160>;
						linux,phandle = <0x160>;
					};

					pinmux_P8_15_gpio_pd_pin {
						pinctrl-single,pins = <0x3c 0x27>;
						phandle = <0x107>;
						linux,phandle = <0x107>;
					};

					pinmux_P8_11_gpio_pd_pin {
						pinctrl-single,pins = <0x34 0x27>;
						phandle = <0xf1>;
						linux,phandle = <0xf1>;
					};

					pinmux_P9_41_gpio_pu_pin {
						pinctrl-single,pins = <0x1b4 0x37>;
						phandle = <0x199>;
						linux,phandle = <0x199>;
					};

					pinmux_P9_16_gpio_pd_pin {
						pinctrl-single,pins = <0x4c 0x27>;
						phandle = <0x13d>;
						linux,phandle = <0x13d>;
					};

					pinmux_P8_08_gpio_pd_pin {
						pinctrl-single,pins = <0x94 0x27>;
						phandle = <0xe2>;
						linux,phandle = <0xe2>;
					};

					pinmux_P9_12_gpio_pd_pin {
						pinctrl-single,pins = <0x78 0x27>;
						phandle = <0x12a>;
						linux,phandle = <0x12a>;
					};

					pinmux_P8_26_gpio_pu_pin {
						pinctrl-single,pins = <0x7c 0x37>;
						phandle = <0x120>;
						linux,phandle = <0x120>;
					};

					pinmux_P9_30_gpio_pu_pin {
						pinctrl-single,pins = <0x198 0x37>;
						phandle = <0x17b>;
						linux,phandle = <0x17b>;
					};

					pinmux_P9_30_pruout_pin {
						pinctrl-single,pins = <0x198 0x25>;
						phandle = <0x17f>;
						linux,phandle = <0x17f>;
					};

					pinmux_P9_27_gpio_pu_pin {
						pinctrl-single,pins = <0x1a4 0x37>;
						phandle = <0x174>;
						linux,phandle = <0x174>;
					};

					pinmux_P8_19_gpio_pu_pin {
						pinctrl-single,pins = <0x20 0x37>;
						phandle = <0x11b>;
						linux,phandle = <0x11b>;
					};

					pinmux_P9_23_gpio_pu_pin {
						pinctrl-single,pins = <0x44 0x37>;
						phandle = <0x15f>;
						linux,phandle = <0x15f>;
					};

					pinmux_P8_15_gpio_pu_pin {
						pinctrl-single,pins = <0x3c 0x37>;
						phandle = <0x106>;
						linux,phandle = <0x106>;
					};

					pinmux_P9_21_pwm_pin {
						pinctrl-single,pins = <0x154 0x33>;
						phandle = <0x154>;
						linux,phandle = <0x154>;
					};

					pinmux_P9_24_pruin_pin {
						pinctrl-single,pins = <0x184 0x36>;
						phandle = <0x169>;
						linux,phandle = <0x169>;
					};

					pinmux_P8_11_gpio_pu_pin {
						pinctrl-single,pins = <0x34 0x37>;
						phandle = <0xf0>;
						linux,phandle = <0xf0>;
					};

					pinmux_P9_16_gpio_pu_pin {
						pinctrl-single,pins = <0x4c 0x37>;
						phandle = <0x13c>;
						linux,phandle = <0x13c>;
					};

					pinmux_P8_08_gpio_pu_pin {
						pinctrl-single,pins = <0x94 0x37>;
						phandle = <0xe1>;
						linux,phandle = <0xe1>;
					};

					pinmux_P9_92_default_pin {
						pinctrl-single,pins = <0x1a0 0x27>;
						phandle = <0x190>;
						linux,phandle = <0x190>;
					};

					pinmux_P9_12_gpio_pu_pin {
						pinctrl-single,pins = <0x78 0x37>;
						phandle = <0x129>;
						linux,phandle = <0x129>;
					};

					pinmux_P9_41_pruin_pin {
						pinctrl-single,pins = <0x1b4 0x25>;
						phandle = <0x19c>;
						linux,phandle = <0x19c>;
					};

					pinmux_P9_30_spi_pin {
						pinctrl-single,pins = <0x198 0x23>;
						phandle = <0x17e>;
						linux,phandle = <0x17e>;
					};

					pinmux_P9_15_pwm_pin {
						pinctrl-single,pins = <0x40 0x26>;
						phandle = <0x139>;
						linux,phandle = <0x139>;
					};

					davinci_mdio_default {
						pinctrl-single,pins = <0x148 0x30 0x14c 0x10>;
						phandle = <0x45>;
						linux,phandle = <0x45>;
					};

					pinmux_P8_17_pwm_pin {
						pinctrl-single,pins = <0x2c 0x24>;
						phandle = <0x114>;
						linux,phandle = <0x114>;
					};

					pinmux_P9_41_default_pin {
						pinctrl-single,pins = <0x1b4 0x27>;
						phandle = <0x197>;
						linux,phandle = <0x197>;
					};

					pinmux_P9_21_i2c_pin {
						pinctrl-single,pins = <0x154 0x32>;
						phandle = <0x153>;
						linux,phandle = <0x153>;
					};

					pinmux_P8_26_default_pin {
						pinctrl-single,pins = <0x7c 0x37>;
						phandle = <0x11e>;
						linux,phandle = <0x11e>;
					};

					pinmux_P9_30_default_pin {
						pinctrl-single,pins = <0x198 0x27>;
						phandle = <0x179>;
						linux,phandle = <0x179>;
					};

					pinmux_mmc1_pins {
						pinctrl-single,pins = <0xf0 0x30 0xf4 0x30 0xf8 0x30 0xfc 0x30 0x100 0x30 0x104 0x30 0x160 0x2f>;
						phandle = <0x35>;
						linux,phandle = <0x35>;
					};

					pinmux_P9_27_default_pin {
						pinctrl-single,pins = <0x1a4 0x27>;
						phandle = <0x172>;
						linux,phandle = <0x172>;
					};

					pinmux_P8_19_default_pin {
						pinctrl-single,pins = <0x20 0x27>;
						phandle = <0x119>;
						linux,phandle = <0x119>;
					};

					pinmux_P9_23_default_pin {
						pinctrl-single,pins = <0x44 0x27>;
						phandle = <0x15d>;
						linux,phandle = <0x15d>;
					};

					pinmux_P8_15_default_pin {
						pinctrl-single,pins = <0x3c 0x27>;
						phandle = <0x104>;
						linux,phandle = <0x104>;
					};

					pinmux_P9_42_pwm_pin {
						pinctrl-single,pins = <0x164 0x20>;
						phandle = <0x18c>;
						linux,phandle = <0x18c>;
					};

					pinmux_P9_18_spi_pin {
						pinctrl-single,pins = <0x158 0x30>;
						phandle = <0x14a>;
						linux,phandle = <0x14a>;
					};

					pinmux_P8_11_default_pin {
						pinctrl-single,pins = <0x34 0x27>;
						phandle = <0xee>;
						linux,phandle = <0xee>;
					};

					pinmux_P9_16_default_pin {
						pinctrl-single,pins = <0x4c 0x27>;
						phandle = <0x13a>;
						linux,phandle = <0x13a>;
					};

					pinmux_P8_08_default_pin {
						pinctrl-single,pins = <0x94 0x37>;
						phandle = <0xdf>;
						linux,phandle = <0xdf>;
					};

					pinmux_P9_12_default_pin {
						pinctrl-single,pins = <0x78 0x37>;
						phandle = <0x127>;
						linux,phandle = <0x127>;
					};

					pinmux_P9_21_uart_pin {
						pinctrl-single,pins = <0x154 0x31>;
						phandle = <0x152>;
						linux,phandle = <0x152>;
					};

					pinmux_P9_92_gpio_pin {
						pinctrl-single,pins = <0x1a0 0x2f>;
						phandle = <0x191>;
						linux,phandle = <0x191>;
					};

					user_leds_s0 {
						pinctrl-single,pins = <0x54 0x7 0x58 0x17 0x5c 0x7 0x60 0x17>;
						phandle = <0x4d>;
						linux,phandle = <0x4d>;
					};

					davinci_mdio_sleep {
						pinctrl-single,pins = <0x148 0x27 0x14c 0x27>;
						phandle = <0x46>;
						linux,phandle = <0x46>;
					};

					pinmux_P8_12_qep_pin {
						pinctrl-single,pins = <0x30 0x24>;
						phandle = <0xf9>;
						linux,phandle = <0xf9>;
					};

					pinmux_P9_23_pwm_pin {
						pinctrl-single,pins = <0x44 0x26>;
						phandle = <0x161>;
						linux,phandle = <0x161>;
					};

					mcasp0_pins_sleep {
						pinctrl-single,pins = <0x1ac 0x27 0x19c 0x27 0x194 0x27 0x190 0x27 0x6c 0x27>;
						phandle = <0x4c>;
						linux,phandle = <0x4c>;
					};

					pinmux_P9_41_gpio_pin {
						pinctrl-single,pins = <0x1b4 0x2f>;
						phandle = <0x198>;
						linux,phandle = <0x198>;
					};

					pinmux_P9_17_pwm_pin {
						pinctrl-single,pins = <0x15c 0x33>;
						phandle = <0x145>;
						linux,phandle = <0x145>;
					};

					pinmux_P9_30_pruin_pin {
						pinctrl-single,pins = <0x198 0x26>;
						phandle = <0x180>;
						linux,phandle = <0x180>;
					};

					pinmux_P9_30_gpio_pin {
						pinctrl-single,pins = <0x198 0x2f>;
						phandle = <0x17a>;
						linux,phandle = <0x17a>;
					};

					pinmux_P9_27_gpio_pin {
						pinctrl-single,pins = <0x1a4 0x2f>;
						phandle = <0x173>;
						linux,phandle = <0x173>;
					};

					pinmux_P9_23_gpio_pin {
						pinctrl-single,pins = <0x44 0x2f>;
						phandle = <0x15e>;
						linux,phandle = <0x15e>;
					};

					mcasp0_pins {
						pinctrl-single,pins = <0x1ac 0x30 0x19c 0x2 0x194 0x10 0x190 0x0 0x6c 0x7>;
						phandle = <0x4b>;
						linux,phandle = <0x4b>;
					};

					pinmux_P8_19_pwm_pin {
						pinctrl-single,pins = <0x20 0x24>;
						phandle = <0x11d>;
						linux,phandle = <0x11d>;
					};

					pinmux_P8_17_gpio_pin {
						pinctrl-single,pins = <0x2c 0x2f>;
						phandle = <0x111>;
						linux,phandle = <0x111>;
					};

					pinmux_P9_16_gpio_pin {
						pinctrl-single,pins = <0x4c 0x2f>;
						phandle = <0x13b>;
						linux,phandle = <0x13b>;
					};

					pinmux_P8_13_gpio_pin {
						pinctrl-single,pins = <0x24 0x2f>;
						phandle = <0xfb>;
						linux,phandle = <0xfb>;
					};

					pinmux_P9_12_gpio_pin {
						pinctrl-single,pins = <0x78 0x2f>;
						phandle = <0x128>;
						linux,phandle = <0x128>;
					};

					pinmux_P9_17_i2c_pin {
						pinctrl-single,pins = <0x15c 0x32>;
						phandle = <0x144>;
						linux,phandle = <0x144>;
					};

					pinmux_P9_42_gpio_pd_pin {
						pinctrl-single,pins = <0x164 0x27>;
						phandle = <0x18b>;
						linux,phandle = <0x18b>;
					};

					pinmux_P9_27_pruin_pin {
						pinctrl-single,pins = <0x1a4 0x26>;
						phandle = <0x178>;
						linux,phandle = <0x178>;
					};

					pinmux_P9_92_qep_pin {
						pinctrl-single,pins = <0x1a0 0x21>;
						phandle = <0x194>;
						linux,phandle = <0x194>;
					};

					pinmux_P9_24_gpio_pd_pin {
						pinctrl-single,pins = <0x184 0x27>;
						phandle = <0x165>;
						linux,phandle = <0x165>;
					};

					pinmux_P8_16_gpio_pd_pin {
						pinctrl-single,pins = <0x38 0x27>;
						phandle = <0x10d>;
						linux,phandle = <0x10d>;
					};

					pinmux_P8_12_gpio_pd_pin {
						pinctrl-single,pins = <0x30 0x27>;
						phandle = <0xf7>;
						linux,phandle = <0xf7>;
					};

					pinmux_P9_42_gpio_pu_pin {
						pinctrl-single,pins = <0x164 0x37>;
						phandle = <0x18a>;
						linux,phandle = <0x18a>;
					};

					pinmux_P9_17_gpio_pd_pin {
						pinctrl-single,pins = <0x15c 0x27>;
						phandle = <0x142>;
						linux,phandle = <0x142>;
					};

					pinmux_P8_09_gpio_pd_pin {
						pinctrl-single,pins = <0x9c 0x27>;
						phandle = <0xe7>;
						linux,phandle = <0xe7>;
					};

					pinmux_P9_13_gpio_pd_pin {
						pinctrl-single,pins = <0x74 0x27>;
						phandle = <0x12e>;
						linux,phandle = <0x12e>;
					};

					pinmux_i2c0_pins {
						pinctrl-single,pins = <0x188 0x30 0x18c 0x30>;
						phandle = <0x2f>;
						linux,phandle = <0x2f>;
					};

					pinmux_P9_24_gpio_pu_pin {
						pinctrl-single,pins = <0x184 0x37>;
						phandle = <0x164>;
						linux,phandle = <0x164>;
					};

					pinmux_P8_16_gpio_pu_pin {
						pinctrl-single,pins = <0x38 0x37>;
						phandle = <0x10c>;
						linux,phandle = <0x10c>;
					};

					pinmux_P8_12_gpio_pu_pin {
						pinctrl-single,pins = <0x30 0x37>;
						phandle = <0xf6>;
						linux,phandle = <0xf6>;
					};

					pinmux_P9_17_gpio_pu_pin {
						pinctrl-single,pins = <0x15c 0x37>;
						phandle = <0x141>;
						linux,phandle = <0x141>;
					};

					pinmux_P8_09_gpio_pu_pin {
						pinctrl-single,pins = <0x9c 0x37>;
						phandle = <0xe6>;
						linux,phandle = <0xe6>;
					};

					pinmux_P9_13_gpio_pu_pin {
						pinctrl-single,pins = <0x74 0x37>;
						phandle = <0x12d>;
						linux,phandle = <0x12d>;
					};

					pinmux_i2c2_pins {
						pinctrl-single,pins = <0x178 0x33 0x17c 0x33>;
						phandle = <0x33>;
						linux,phandle = <0x33>;
					};

					pinmux_uart0_pins {
						pinctrl-single,pins = <0x170 0x30 0x174 0x0>;
						phandle = <0x2e>;
						linux,phandle = <0x2e>;
					};

					pinmux_P9_42_default_pin {
						pinctrl-single,pins = <0x164 0x27>;
						phandle = <0x188>;
						linux,phandle = <0x188>;
					};

					pinmux_P8_09_timer_pin {
						pinctrl-single,pins = <0x9c 0x32>;
						phandle = <0xe8>;
						linux,phandle = <0xe8>;
					};

					pinmux_P9_24_default_pin {
						pinctrl-single,pins = <0x184 0x37>;
						phandle = <0x162>;
						linux,phandle = <0x162>;
					};

					pinmux_P8_16_default_pin {
						pinctrl-single,pins = <0x38 0x27>;
						phandle = <0x10a>;
						linux,phandle = <0x10a>;
					};

					pinmux_P8_12_default_pin {
						pinctrl-single,pins = <0x30 0x27>;
						phandle = <0xf4>;
						linux,phandle = <0xf4>;
					};

					pinmux_P9_17_default_pin {
						pinctrl-single,pins = <0x15c 0x37>;
						phandle = <0x13f>;
						linux,phandle = <0x13f>;
					};

					pinmux_P9_27_qep_pin {
						pinctrl-single,pins = <0x1a4 0x21>;
						phandle = <0x176>;
						linux,phandle = <0x176>;
					};

					pinmux_P8_09_default_pin {
						pinctrl-single,pins = <0x9c 0x37>;
						phandle = <0xe4>;
						linux,phandle = <0xe4>;
					};

					pinmux_P9_92_pruin_pin {
						pinctrl-single,pins = <0x1a0 0x26>;
						phandle = <0x196>;
						linux,phandle = <0x196>;
					};

					pinmux_P9_13_default_pin {
						pinctrl-single,pins = <0x74 0x37>;
						phandle = <0x12b>;
						linux,phandle = <0x12b>;
					};

					pinmux_P9_26_uart_pin {
						pinctrl-single,pins = <0x180 0x30>;
						phandle = <0x16e>;
						linux,phandle = <0x16e>;
					};

					pinmux_P9_22_uart_pin {
						pinctrl-single,pins = <0x150 0x31>;
						phandle = <0x15a>;
						linux,phandle = <0x15a>;
					};

					pinmux_P9_21_spi_pin {
						pinctrl-single,pins = <0x154 0x30>;
						phandle = <0x151>;
						linux,phandle = <0x151>;
					};

					pinmux_P9_11_uart_pin {
						pinctrl-single,pins = <0x70 0x36>;
						phandle = <0x126>;
						linux,phandle = <0x126>;
					};

					pinmux_P8_14_pwm_pin {
						pinctrl-single,pins = <0x28 0x24>;
						phandle = <0x103>;
						linux,phandle = <0x103>;
					};
				};

				wkup_m3_ipc@1324 {
					reg = <0x1324 0x24>;
					interrupts = <0x4e>;
					compatible = "ti,am3352-wkup-m3-ipc";
					mboxes = <0x28 0x29>;
					ti,scale-data-fw = "am335x-bone-scale-data.bin";
					phandle = <0x8c>;
					linux,phandle = <0x8c>;
					ti,rproc = <0x27>;
				};

				dma-router@f90 {
					reg = <0xf90 0x40>;
					dma-requests = <0x20>;
					compatible = "ti,am335x-edma-crossbar";
					dma-masters = <0x2a>;
					#dma-cells = <0x3>;
					phandle = <0x34>;
					linux,phandle = <0x34>;
				};

				scm_conf@0 {
					reg = <0x0 0x800>;
					compatible = "syscon";
					#address-cells = <0x1>;
					phandle = <0x3b>;
					#size-cells = <0x1>;
					linux,phandle = <0x3b>;

					clocks {
						#address-cells = <0x1>;
						phandle = <0x80>;
						#size-cells = <0x0>;
						linux,phandle = <0x80>;

						sys_clkin_ck {
							reg = <0x40>;
							#clock-cells = <0x0>;
							compatible = "ti,mux-clock";
							ti,bit-shift = <0x16>;
							clocks = <0x22 0x23 0x24 0x25>;
							phandle = <0x5>;
							linux,phandle = <0x5>;
						};

						rng_fck {
							#clock-cells = <0x0>;
							compatible = "fixed-factor-clock";
							clocks = <0x5>;
							clock-div = <0x1>;
							phandle = <0x88>;
							clock-mult = <0x1>;
							linux,phandle = <0x88>;
						};

						ehrpwm2_tbclk@44e10664 {
							reg = <0x664>;
							#clock-cells = <0x0>;
							compatible = "ti,gate-clock";
							ti,bit-shift = <0x2>;
							clocks = <0x26>;
							phandle = <0x8b>;
							linux,phandle = <0x8b>;
						};

						mcasp0_fck {
							#clock-cells = <0x0>;
							compatible = "fixed-factor-clock";
							clocks = <0x5>;
							clock-div = <0x1>;
							phandle = <0x82>;
							clock-mult = <0x1>;
							linux,phandle = <0x82>;
						};

						mcasp1_fck {
							#clock-cells = <0x0>;
							compatible = "fixed-factor-clock";
							clocks = <0x5>;
							clock-div = <0x1>;
							phandle = <0x83>;
							clock-mult = <0x1>;
							linux,phandle = <0x83>;
						};

						ehrpwm1_tbclk@44e10664 {
							reg = <0x664>;
							#clock-cells = <0x0>;
							compatible = "ti,gate-clock";
							ti,bit-shift = <0x1>;
							clocks = <0x26>;
							phandle = <0x8a>;
							linux,phandle = <0x8a>;
						};

						adc_tsc_fck {
							#clock-cells = <0x0>;
							compatible = "fixed-factor-clock";
							clocks = <0x5>;
							clock-div = <0x1>;
							phandle = <0x81>;
							clock-mult = <0x1>;
							linux,phandle = <0x81>;
						};

						smartreflex0_fck {
							#clock-cells = <0x0>;
							compatible = "fixed-factor-clock";
							clocks = <0x5>;
							clock-div = <0x1>;
							phandle = <0x84>;
							clock-mult = <0x1>;
							linux,phandle = <0x84>;
						};

						smartreflex1_fck {
							#clock-cells = <0x0>;
							compatible = "fixed-factor-clock";
							clocks = <0x5>;
							clock-div = <0x1>;
							phandle = <0x85>;
							clock-mult = <0x1>;
							linux,phandle = <0x85>;
						};

						ehrpwm0_tbclk@44e10664 {
							reg = <0x664>;
							#clock-cells = <0x0>;
							compatible = "ti,gate-clock";
							ti,bit-shift = <0x0>;
							clocks = <0x26>;
							phandle = <0x89>;
							linux,phandle = <0x89>;
						};

						dcan0_fck {
							#clock-cells = <0x0>;
							compatible = "fixed-factor-clock";
							clocks = <0x5>;
							clock-div = <0x1>;
							phandle = <0x3a>;
							clock-mult = <0x1>;
							linux,phandle = <0x3a>;
						};

						dcan1_fck {
							#clock-cells = <0x0>;
							compatible = "fixed-factor-clock";
							clocks = <0x5>;
							clock-div = <0x1>;
							phandle = <0x3c>;
							clock-mult = <0x1>;
							linux,phandle = <0x3c>;
						};

						aes0_fck {
							#clock-cells = <0x0>;
							compatible = "fixed-factor-clock";
							clocks = <0x5>;
							clock-div = <0x1>;
							phandle = <0x87>;
							clock-mult = <0x1>;
							linux,phandle = <0x87>;
						};

						sha0_fck {
							#clock-cells = <0x0>;
							compatible = "fixed-factor-clock";
							clocks = <0x5>;
							clock-div = <0x1>;
							phandle = <0x86>;
							clock-mult = <0x1>;
							linux,phandle = <0x86>;
						};
					};
				};
			};
		};

		epwmss@48300000 {
			reg = <0x48300000 0x10>;
			compatible = "ti,am33xx-pwmss";
			ranges = <0x48300100 0x48300100 0x80 0x48300180 0x48300180 0x80 0x48300200 0x48300200 0x80>;
			status = "okay";
			#address-cells = <0x1>;
			ti,hwmods = "epwmss0";
			phandle = <0xba>;
			#size-cells = <0x1>;
			linux,phandle = <0xba>;

			eqep@0x48300180 {
				count_mode = <0x0>;
				reg = <0x48300180 0x80>;
				interrupts = <0x4f>;
				pinctrl-0;
				compatible = "ti,am33xx-eqep";
				invert_qa = <0x1>;
				invert_qb = <0x1>;
				invert_qi = <0x0>;
				invert_qs = <0x0>;
				swap_inputs = <0x0>;
				status = "okay";
				ti,hwmods = "eqep0";
				phandle = <0xbd>;
				pinctrl-names = "default";
				linux,phandle = <0xbd>;
				interrupt-parent = <0x1>;
			};

			ehrpwm@48300200 {
				reg = <0x48300200 0x80>;
				pinctrl-0;
				compatible = "ti,am33xx-ehrpwm";
				#pwm-cells = <0x3>;
				status = "okay";
				ti,hwmods = "ehrpwm0";
				phandle = <0xbc>;
				pinctrl-names = "default";
				linux,phandle = <0xbc>;
			};

			ecap@48300100 {
				reg = <0x48300100 0x80>;
				interrupts = <0x1f>;
				pinctrl-0;
				compatible = "ti,am33xx-ecap";
				interrupt-names = "ecap0";
				#pwm-cells = <0x3>;
				status = "okay";
				ti,hwmods = "ecap0";
				phandle = <0xbb>;
				pinctrl-names = "default";
				linux,phandle = <0xbb>;
			};
		};

		epwmss@48302000 {
			reg = <0x48302000 0x10>;
			compatible = "ti,am33xx-pwmss";
			ranges = <0x48302100 0x48302100 0x80 0x48302180 0x48302180 0x80 0x48302200 0x48302200 0x80>;
			status = "okay";
			#address-cells = <0x1>;
			ti,hwmods = "epwmss1";
			phandle = <0xbe>;
			#size-cells = <0x1>;
			linux,phandle = <0xbe>;

			eqep@0x48302180 {
				count_mode = <0x0>;
				reg = <0x48302180 0x80>;
				interrupts = <0x58>;
				pinctrl-0;
				compatible = "ti,am33xx-eqep";
				invert_qa = <0x1>;
				invert_qb = <0x1>;
				invert_qi = <0x0>;
				invert_qs = <0x0>;
				swap_inputs = <0x0>;
				status = "okay";
				ti,hwmods = "eqep1";
				phandle = <0xc1>;
				pinctrl-names = "default";
				linux,phandle = <0xc1>;
				interrupt-parent = <0x1>;
			};

			ehrpwm@48302200 {
				reg = <0x48302200 0x80>;
				pinctrl-0;
				compatible = "ti,am33xx-ehrpwm";
				#pwm-cells = <0x3>;
				status = "okay";
				ti,hwmods = "ehrpwm1";
				phandle = <0xc0>;
				pinctrl-names = "default";
				linux,phandle = <0xc0>;
			};

			ecap@48302100 {
				reg = <0x48302100 0x80>;
				interrupts = <0x2f>;
				compatible = "ti,am33xx-ecap";
				interrupt-names = "ecap1";
				#pwm-cells = <0x3>;
				status = "disabled";
				ti,hwmods = "ecap1";
				phandle = <0xbf>;
				linux,phandle = <0xbf>;
			};
		};

		epwmss@48304000 {
			reg = <0x48304000 0x10>;
			compatible = "ti,am33xx-pwmss";
			ranges = <0x48304100 0x48304100 0x80 0x48304180 0x48304180 0x80 0x48304200 0x48304200 0x80>;
			status = "okay";
			#address-cells = <0x1>;
			ti,hwmods = "epwmss2";
			phandle = <0xc2>;
			#size-cells = <0x1>;
			linux,phandle = <0xc2>;

			eqep@0x48304180 {
				count_mode = <0x0>;
				reg = <0x48304180 0x80>;
				interrupts = <0x59>;
				pinctrl-0;
				compatible = "ti,am33xx-eqep";
				invert_qa = <0x1>;
				invert_qb = <0x1>;
				invert_qi = <0x0>;
				invert_qs = <0x0>;
				swap_inputs = <0x0>;
				status = "okay";
				ti,hwmods = "eqep2";
				phandle = <0xc5>;
				pinctrl-names = "default";
				linux,phandle = <0xc5>;
				interrupt-parent = <0x1>;
			};

			ehrpwm@48304200 {
				reg = <0x48304200 0x80>;
				pinctrl-0;
				compatible = "ti,am33xx-ehrpwm";
				#pwm-cells = <0x3>;
				status = "okay";
				ti,hwmods = "ehrpwm2";
				phandle = <0xc4>;
				pinctrl-names = "default";
				linux,phandle = <0xc4>;
			};

			ecap@48304100 {
				reg = <0x48304100 0x80>;
				interrupts = <0x3d>;
				pinctrl-0;
				compatible = "ti,am33xx-ecap";
				interrupt-names = "ecap2";
				#pwm-cells = <0x3>;
				status = "okay";
				ti,hwmods = "ecap2";
				phandle = <0xc3>;
				pinctrl-names = "default";
				linux,phandle = <0xc3>;
			};
		};

		P9_22_pinmux {
			pinctrl-0 = <0x155>;
			pinctrl-1 = <0x156>;
			pinctrl-2 = <0x157>;
			pinctrl-3 = <0x158>;
			pinctrl-4 = <0x159>;
			pinctrl-5 = <0x15a>;
			pinctrl-6 = <0x15b>;
			pinctrl-7 = <0x15c>;
			compatible = "bone-pinmux-helper";
			status = "okay";
			pinctrl-names = "default", "gpio", "gpio_pu", "gpio_pd", "spi", "uart", "i2c", "pwm";
		};

		P9_18_pinmux {
			pinctrl-0 = <0x146>;
			pinctrl-1 = <0x147>;
			pinctrl-2 = <0x148>;
			pinctrl-3 = <0x149>;
			pinctrl-4 = <0x14a>;
			pinctrl-5 = <0x14b>;
			pinctrl-6 = <0x14c>;
			compatible = "bone-pinmux-helper";
			status = "okay";
			pinctrl-names = "default", "gpio", "gpio_pu", "gpio_pd", "spi", "i2c", "pwm";
		};

		P9_13_pinmux {
			pinctrl-0 = <0x12b>;
			pinctrl-1 = <0x12c>;
			pinctrl-2 = <0x12d>;
			pinctrl-3 = <0x12e>;
			pinctrl-4 = <0x12f>;
			compatible = "bone-pinmux-helper";
			status = "okay";
			pinctrl-names = "default", "gpio", "gpio_pu", "gpio_pd", "uart";
		};

		spi@48030000 {
			reg = <0x48030000 0x400>;
			dmas = <0x2a 0x10 0x0 0x2a 0x11 0x0 0x2a 0x12 0x0 0x2a 0x13 0x0>;
			interrupts = <0x41>;
			pinctrl-0;
			compatible = "ti,omap4-mcspi";
			status = "okay";
			#address-cells = <0x1>;
			ti,hwmods = "spi0";
			phandle = <0xb5>;
			ti,spi-num-cs = <0x2>;
			#size-cells = <0x0>;
			dma-names = "tx0", "rx0", "tx1", "rx1";
			pinctrl-names = "default";
			linux,phandle = <0xb5>;

			spi0channel@0 {
				reg = <0x0>;
				spi-cpha;
				compatible = "spidev";
				spi-max-frequency = <0xf42400>;
				#address-cells = <0x1>;
				#size-cells = <0x0>;
			};

			spi0channel@1 {
				reg = <0x1>;
				compatible = "spidev";
				spi-max-frequency = <0xf42400>;
				#address-cells = <0x1>;
				#size-cells = <0x0>;
			};
		};

		P8_16_pinmux {
			pinctrl-0 = <0x10a>;
			pinctrl-1 = <0x10b>;
			pinctrl-2 = <0x10c>;
			pinctrl-3 = <0x10d>;
			pinctrl-4 = <0x10e>;
			pinctrl-5 = <0x10f>;
			compatible = "bone-pinmux-helper";
			status = "okay";
			pinctrl-names = "default", "gpio", "gpio_pu", "gpio_pd", "pruin", "qep";
		};

		P8_11_pinmux {
			pinctrl-0 = <0xee>;
			pinctrl-1 = <0xef>;
			pinctrl-2 = <0xf0>;
			pinctrl-3 = <0xf1>;
			pinctrl-4 = <0xf2>;
			pinctrl-5 = <0xf3>;
			compatible = "bone-pinmux-helper";
			status = "okay";
			pinctrl-names = "default", "gpio", "gpio_pu", "gpio_pd", "pruout", "qep";
		};

		P8_07_pinmux {
			pinctrl-0 = <0xda>;
			pinctrl-1 = <0xdb>;
			pinctrl-2 = <0xdc>;
			pinctrl-3 = <0xdd>;
			pinctrl-4 = <0xde>;
			compatible = "bone-pinmux-helper";
			status = "okay";
			pinctrl-names = "default", "gpio", "gpio_pu", "gpio_pd", "timer";
		};

		aes@53500000 {
			reg = <0x53500000 0xa0>;
			dmas = <0x2a 0x6 0x0 0x2a 0x5 0x0>;
			interrupts = <0x67>;
			compatible = "ti,omap4-aes";
			status = "okay";
			ti,hwmods = "aes";
			phandle = <0xd3>;
			dma-names = "tx", "rx";
			linux,phandle = <0xd3>;
		};

		tptc@49a00000 {
			reg = <0x49a00000 0x100000>;
			interrupts = <0x72>;
			compatible = "ti,edma3-tptc";
			interrupt-names = "edma3_tcerrint";
			ti,hwmods = "tptc2";
			phandle = <0x2d>;
			linux,phandle = <0x2d>;
		};

		P9_42_pinmux {
			pinctrl-0 = <0x188>;
			pinctrl-1 = <0x189>;
			pinctrl-2 = <0x18a>;
			pinctrl-3 = <0x18b>;
			pinctrl-4 = <0x18c>;
			pinctrl-5 = <0x18d>;
			pinctrl-6 = <0x18e>;
			pinctrl-7 = <0x18f>;
			compatible = "bone-pinmux-helper";
			status = "okay";
			pinctrl-names = "default", "gpio", "gpio_pu", "gpio_pd", "pwm", "uart", "spics", "spiclk";
		};

		spi@481a0000 {
			reg = <0x481a0000 0x400>;
			dmas = <0x2a 0x2a 0x0 0x2a 0x2b 0x0 0x2a 0x2c 0x0 0x2a 0x2d 0x0>;
			interrupts = <0x7d>;
			pinctrl-0;
			compatible = "ti,omap4-mcspi";
			status = "okay";
			#address-cells = <0x1>;
			ti,hwmods = "spi1";
			phandle = <0xb6>;
			ti,spi-num-cs = <0x2>;
			#size-cells = <0x0>;
			dma-names = "tx0", "rx0", "tx1", "rx1";
			pinctrl-names = "default";
			linux,phandle = <0xb6>;

			spi1channel@0 {
				reg = <0x0>;
				spi-cpha;
				compatible = "spidev";
				spi-max-frequency = <0xf42400>;
				#address-cells = <0x1>;
				#size-cells = <0x0>;
			};

			spi1channel@1 {
				reg = <0x1>;
				compatible = "spidev";
				spi-max-frequency = <0xf42400>;
				#address-cells = <0x1>;
				#size-cells = <0x0>;
			};
		};

		rng@48310000 {
			reg = <0x48310000 0x2000>;
			interrupts = <0x6f>;
			compatible = "ti,omap4-rng";
			ti,hwmods = "rng";
			phandle = <0xd5>;
			linux,phandle = <0xd5>;
		};

		P9_24_pinmux {
			pinctrl-0 = <0x162>;
			pinctrl-1 = <0x163>;
			pinctrl-2 = <0x164>;
			pinctrl-3 = <0x165>;
			pinctrl-4 = <0x166>;
			pinctrl-5 = <0x167>;
			pinctrl-6 = <0x168>;
			pinctrl-7 = <0x169>;
			compatible = "bone-pinmux-helper";
			status = "okay";
			pinctrl-names = "default", "gpio", "gpio_pu", "gpio_pd", "uart", "can", "i2c", "pruin";
		};

		can@481d0000 {
			reg = <0x481d0000 0x2000>;
			interrupts = <0x37>;
			pinctrl-0;
			compatible = "ti,am3352-d_can";
			clock-names = "fck";
			clocks = <0x3c>;
			status = "okay";
			ti,hwmods = "d_can1";
			phandle = <0xac>;
			syscon-raminit = <0x3b 0x644 0x1>;
			pinctrl-names = "default";
			linux,phandle = <0xac>;
		};

		can@481cc000 {
			reg = <0x481cc000 0x2000>;
			interrupts = <0x34>;
			pinctrl-0;
			compatible = "ti,am3352-d_can";
			clock-names = "fck";
			clocks = <0x3a>;
			status = "okay";
			ti,hwmods = "d_can0";
			phandle = <0xab>;
			syscon-raminit = <0x3b 0x644 0x0>;
			pinctrl-names = "default";
			linux,phandle = <0xab>;
		};

		P9_15_pinmux {
			pinctrl-0 = <0x135>;
			pinctrl-1 = <0x136>;
			pinctrl-2 = <0x137>;
			pinctrl-3 = <0x138>;
			pinctrl-4 = <0x139>;
			compatible = "bone-pinmux-helper";
			status = "okay";
			pinctrl-names = "default", "gpio", "gpio_pu", "gpio_pd", "pwm";
		};

		gpio@4804c000 {
			reg = <0x4804c000 0x1000>;
			interrupts = <0x62>;
			#gpio-cells = <0x2>;
			compatible = "ti,omap4-gpio";
			#interrupt-cells = <0x2>;
			ti,hwmods = "gpio2";
			phandle = <0x4e>;
			interrupt-controller;
			gpio-controller;
			linux,phandle = <0x4e>;
		};

		sham@53100000 {
			reg = <0x53100000 0x200>;
			dmas = <0x2a 0x24 0x0>;
			interrupts = <0x6d>;
			compatible = "ti,omap4-sham";
			status = "okay";
			ti,hwmods = "sham";
			phandle = <0xd2>;
			dma-names = "rx";
			linux,phandle = <0xd2>;
		};

		elm@48080000 {
			reg = <0x48080000 0x2000>;
			interrupts = <0x4>;
			compatible = "ti,am3352-elm";
			status = "disabled";
			ti,hwmods = "elm";
			phandle = <0xcd>;
			linux,phandle = <0xcd>;
		};

		tscadc@44e0d000 {
			reg = <0x44e0d000 0x1000>;
			interrupts = <0x10>;
			compatible = "ti,am3359-tscadc";
			status = "disabled";
			ti,hwmods = "adc_tsc";
			phandle = <0xcf>;
			linux,phandle = <0xcf>;
			interrupt-parent = <0x1>;

			adc {
				compatible = "ti,am3359-adc";
				phandle = <0xd0>;
				#io-channel-cells = <0x1>;
				linux,phandle = <0xd0>;
			};

			tsc {
				compatible = "ti,am3359-tsc";
			};
		};

		mcasp@48038000 {
			reg = <0x48038000 0x2000 0x46000000 0x400000>;
			dmas = <0x2a 0x8 0x2 0x2a 0x9 0x2>;
			interrupts = <0x50 0x51>;
			tx-num-evt = <0x1>;
			pinctrl-0 = <0x4b>;
			pinctrl-1 = <0x4c>;
			reg-names = "mpu", "dat";
			compatible = "ti,am33xx-mcasp-audio";
			interrupt-names = "tx", "rx";
			tdm-slots = <0x2>;
			rx-num-evt = <0x1>;
			serial-dir = <0x0 0x0 0x1 0x0>;
			status = "okay";
			op-mode = <0x0>;
			ti,hwmods = "mcasp0";
			phandle = <0x56>;
			dma-names = "tx", "rx";
			pinctrl-names = "default", "sleep";
			linux,phandle = <0x56>;
		};

		mcasp@4803C000 {
			reg = <0x4803c000 0x2000 0x46400000 0x400000>;
			dmas = <0x2a 0xa 0x2 0x2a 0xb 0x2>;
			interrupts = <0x52 0x53>;
			reg-names = "mpu", "dat";
			compatible = "ti,am33xx-mcasp-audio";
			interrupt-names = "tx", "rx";
			status = "okay";
			ti,hwmods = "mcasp1";
			phandle = <0xd4>;
			dma-names = "tx", "rx";
			linux,phandle = <0xd4>;
		};

		P8_18_pinmux {
			pinctrl-0 = <0x115>;
			pinctrl-1 = <0x116>;
			pinctrl-2 = <0x117>;
			pinctrl-3 = <0x118>;
			compatible = "bone-pinmux-helper";
			status = "okay";
			pinctrl-names = "default", "gpio", "gpio_pu", "gpio_pd";
		};

		P8_13_pinmux {
			pinctrl-0 = <0xfa>;
			pinctrl-1 = <0xfb>;
			pinctrl-2 = <0xfc>;
			pinctrl-3 = <0xfd>;
			pinctrl-4 = <0xfe>;
			compatible = "bone-pinmux-helper";
			status = "okay";
			pinctrl-names = "default", "gpio", "gpio_pu", "gpio_pd", "pwm";
		};

		gpio@481ac000 {
			reg = <0x481ac000 0x1000>;
			interrupts = <0x20>;
			#gpio-cells = <0x2>;
			compatible = "ti,omap4-gpio";
			#interrupt-cells = <0x2>;
			ti,hwmods = "gpio3";
			phandle = <0x8f>;
			interrupt-controller;
			gpio-controller;
			linux,phandle = <0x8f>;
		};

		gpio@481ae000 {
			reg = <0x481ae000 0x1000>;
			interrupts = <0x3e>;
			#gpio-cells = <0x2>;
			compatible = "ti,omap4-gpio";
			#interrupt-cells = <0x2>;
			ti,hwmods = "gpio4";
			phandle = <0x90>;
			interrupt-controller;
			gpio-controller;
			linux,phandle = <0x90>;
		};

		P8_09_pinmux {
			pinctrl-0 = <0xe4>;
			pinctrl-1 = <0xe5>;
			pinctrl-2 = <0xe6>;
			pinctrl-3 = <0xe7>;
			pinctrl-4 = <0xe8>;
			compatible = "bone-pinmux-helper";
			status = "okay";
			pinctrl-names = "default", "gpio", "gpio_pu", "gpio_pd", "timer";
		};

		serial@48022000 {
			reg = <0x48022000 0x2000>;
			dmas = <0x2a 0x1c 0x0 0x2a 0x1d 0x0>;
			interrupts = <0x49>;
			pinctrl-0;
			compatible = "ti,am3352-uart", "ti,omap3-uart";
			clock-frequency = <0x2dc6c00>;
			status = "okay";
			ti,hwmods = "uart2";
			phandle = <0x92>;
			dma-names = "tx", "rx";
			pinctrl-names = "default";
			linux,phandle = <0x92>;
		};

		serial@48024000 {
			reg = <0x48024000 0x2000>;
			dmas = <0x2a 0x1e 0x0 0x2a 0x1f 0x0>;
			interrupts = <0x4a>;
			pinctrl-0;
			compatible = "ti,am3352-uart", "ti,omap3-uart";
			clock-frequency = <0x2dc6c00>;
			status = "okay";
			ti,hwmods = "uart3";
			phandle = <0x93>;
			dma-names = "tx", "rx";
			pinctrl-names = "default";
			linux,phandle = <0x93>;
		};

		gpio@44e07000 {
			reg = <0x44e07000 0x1000>;
			interrupts = <0x60>;
			#gpio-cells = <0x2>;
			compatible = "ti,omap4-gpio";
			#interrupt-cells = <0x2>;
			ti,hwmods = "gpio1";
			phandle = <0x37>;
			interrupt-controller;
			gpio-controller;
			linux,phandle = <0x37>;
		};

		mmc@47810000 {
			reg = <0x47810000 0x1000>;
			interrupts = <0x1d>;
			compatible = "ti,omap4-hsmmc";
			status = "disabled";
			ti,hwmods = "mmc3";
			phandle = <0xa8>;
			linux,phandle = <0xa8>;
			ti,needs-special-reset;
			interrupt-parent = <0x1>;
		};

		P9_30_pinmux {
			pinctrl-0 = <0x179>;
			pinctrl-1 = <0x17a>;
			pinctrl-2 = <0x17b>;
			pinctrl-3 = <0x17c>;
			pinctrl-4 = <0x17d>;
			pinctrl-5 = <0x17e>;
			pinctrl-6 = <0x17f>;
			pinctrl-7 = <0x180>;
			compatible = "bone-pinmux-helper";
			status = "okay";
			pinctrl-names = "default", "gpio", "gpio_pu", "gpio_pd", "pwm", "spi", "pruout", "pruin";
		};

		P9_91_pinmux {
			pinctrl-0 = <0x181>;
			pinctrl-1 = <0x182>;
			pinctrl-2 = <0x183>;
			pinctrl-3 = <0x184>;
			pinctrl-4 = <0x185>;
			pinctrl-5 = <0x186>;
			pinctrl-6 = <0x187>;
			compatible = "bone-pinmux-helper";
			status = "okay";
			pinctrl-names = "default", "gpio", "gpio_pu", "gpio_pd", "qep", "pruout", "pruin";
		};

		P9_26_pinmux {
			pinctrl-0 = <0x16a>;
			pinctrl-1 = <0x16b>;
			pinctrl-2 = <0x16c>;
			pinctrl-3 = <0x16d>;
			pinctrl-4 = <0x16e>;
			pinctrl-5 = <0x16f>;
			pinctrl-6 = <0x170>;
			pinctrl-7 = <0x171>;
			compatible = "bone-pinmux-helper";
			status = "okay";
			pinctrl-names = "default", "gpio", "gpio_pu", "gpio_pd", "uart", "can", "i2c", "pruin";
		};

		mmc@48060000 {
			reg = <0x48060000 0x1000>;
			dmas = <0x34 0x18 0x0 0x0 0x34 0x19 0x0 0x0>;
			cd-gpios = <0x37 0x6 0x0>;
			interrupts = <0x40>;
			vmmc-supply = <0x38>;
			pinctrl-0 = <0x35>;
			pinctrl-1 = <0x36>;
			compatible = "ti,omap4-hsmmc";
			cd-inverted;
			bus-width = <0x4>;
			ti,needs-special-hs-handling;
			ti,dual-volt;
			status = "okay";
			ti,hwmods = "mmc1";
			phandle = <0xa6>;
			dma-names = "tx", "rx";
			pinctrl-names = "default", "sleep";
			linux,phandle = <0xa6>;
			ti,needs-special-reset;
			interrupt-parent = <0x1>;
		};

		pruss@4a300000 {
			reg = <0x4a300000 0x2000 0x4a302000 0x2000 0x4a310000 0x3000 0x4a320000 0x2000 0x4a326000 0x2000>;
			interrupts = <0x14 0x15 0x16 0x17 0x18 0x19 0x1a 0x1b>;
			reg-names = "dram0", "dram1", "shrdram2", "intc", "cfg";
			compatible = "ti,am3352-pruss";
			ranges;
			status = "okay";
			#address-cells = <0x1>;
			ti,hwmods = "pruss";
			phandle = <0xca>;
			#size-cells = <0x1>;
			linux,phandle = <0xca>;

			pru@4a334000 {
				reg = <0x4a334000 0x2000 0x4a322000 0x400 0x4a322400 0x100>;
				reg-names = "iram", "control", "debug";
				compatible = "ti,am3352-pru-rproc";
				mboxes = <0x28 0x48>;
				phandle = <0xcb>;
				linux,phandle = <0xcb>;
			};

			pru@4a338000 {
				reg = <0x4a338000 0x2000 0x4a324000 0x400 0x4a324400 0x100>;
				reg-names = "iram", "control", "debug";
				compatible = "ti,am3352-pru-rproc";
				mboxes = <0x28 0x49>;
				phandle = <0xcc>;
				linux,phandle = <0xcc>;
			};
		};

		P9_21_pinmux {
			pinctrl-0 = <0x14d>;
			pinctrl-1 = <0x14e>;
			pinctrl-2 = <0x14f>;
			pinctrl-3 = <0x150>;
			pinctrl-4 = <0x151>;
			pinctrl-5 = <0x152>;
			pinctrl-6 = <0x153>;
			pinctrl-7 = <0x154>;
			compatible = "bone-pinmux-helper";
			status = "okay";
			pinctrl-names = "default", "gpio", "gpio_pu", "gpio_pd", "spi", "uart", "i2c", "pwm";
		};

		mailbox@480C8000 {
			reg = <0x480c8000 0x200>;
			interrupts = <0x4d>;
			compatible = "ti,omap4-mailbox";
			ti,mbox-num-fifos = <0x8>;
			ti,mbox-num-users = <0x4>;
			#mbox-cells = <0x1>;
			ti,hwmods = "mailbox";
			phandle = <0x28>;
			linux,phandle = <0x28>;

			mbox_pru0 {
				ti,mbox-rx = <0x3 0x0 0x0>;
				ti,mbox-tx = <0x2 0x0 0x0>;
				phandle = <0x48>;
				linux,phandle = <0x48>;
			};

			mbox_pru1 {
				ti,mbox-rx = <0x5 0x0 0x0>;
				ti,mbox-tx = <0x4 0x0 0x0>;
				phandle = <0x49>;
				linux,phandle = <0x49>;
			};

			wkup_m3 {
				ti,mbox-rx = <0x0 0x0 0x3>;
				ti,mbox-tx = <0x0 0x0 0x0>;
				ti,mbox-send-noirq;
				phandle = <0x29>;
				linux,phandle = <0x29>;
			};
		};

		serial@481a6000 {
			reg = <0x481a6000 0x2000>;
			interrupts = <0x2c>;
			compatible = "ti,am3352-uart", "ti,omap3-uart";
			clock-frequency = <0x2dc6c00>;
			status = "disabled";
			ti,hwmods = "uart4";
			phandle = <0x94>;
			linux,phandle = <0x94>;
		};

		serial@481a8000 {
			reg = <0x481a8000 0x2000>;
			interrupts = <0x2d>;
			pinctrl-0;
			compatible = "ti,am3352-uart", "ti,omap3-uart";
			clock-frequency = <0x2dc6c00>;
			status = "okay";
			ti,hwmods = "uart5";
			phandle = <0x95>;
			pinctrl-names = "default";
			linux,phandle = <0x95>;
		};

		serial@481aa000 {
			reg = <0x481aa000 0x2000>;
			interrupts = <0x2e>;
			compatible = "ti,am3352-uart", "ti,omap3-uart";
			clock-frequency = <0x2dc6c00>;
			status = "disabled";
			ti,hwmods = "uart6";
			phandle = <0x96>;
			linux,phandle = <0x96>;
		};

		P9_17_pinmux {
			pinctrl-0 = <0x13f>;
			pinctrl-1 = <0x140>;
			pinctrl-2 = <0x141>;
			pinctrl-3 = <0x142>;
			pinctrl-4 = <0x143>;
			pinctrl-5 = <0x144>;
			pinctrl-6 = <0x145>;
			compatible = "bone-pinmux-helper";
			status = "okay";
			pinctrl-names = "default", "gpio", "gpio_pu", "gpio_pd", "spi", "i2c", "pwm";
		};

		P9_12_pinmux {
			pinctrl-0 = <0x127>;
			pinctrl-1 = <0x128>;
			pinctrl-2 = <0x129>;
			pinctrl-3 = <0x12a>;
			compatible = "bone-pinmux-helper";
			status = "okay";
			pinctrl-names = "default", "gpio", "gpio_pu", "gpio_pd";
		};

		timer@48040000 {
			reg = <0x48040000 0x400>;
			interrupts = <0x44>;
			compatible = "ti,am335x-timer";
			status = "disabled";
			ti,hwmods = "timer2";
			phandle = <0xae>;
			linux,phandle = <0xae>;
		};

		timer@48042000 {
			reg = <0x48042000 0x400>;
			interrupts = <0x45>;
			compatible = "ti,am335x-timer";
			ti,hwmods = "timer3";
			phandle = <0xaf>;
			linux,phandle = <0xaf>;
		};

		timer@48044000 {
			reg = <0x48044000 0x400>;
			interrupts = <0x5c>;
			compatible = "ti,am335x-timer";
			ti,timer-pwm;
			ti,hwmods = "timer4";
			phandle = <0xb0>;
			linux,phandle = <0xb0>;
		};

		timer@48046000 {
			reg = <0x48046000 0x400>;
			interrupts = <0x5d>;
			compatible = "ti,am335x-timer";
			ti,timer-pwm;
			ti,hwmods = "timer5";
			phandle = <0xb1>;
			linux,phandle = <0xb1>;
		};

		timer@48048000 {
			reg = <0x48048000 0x400>;
			interrupts = <0x5e>;
			compatible = "ti,am335x-timer";
			ti,timer-pwm;
			ti,hwmods = "timer6";
			phandle = <0xb2>;
			linux,phandle = <0xb2>;
		};

		timer@4804a000 {
			reg = <0x4804a000 0x400>;
			interrupts = <0x5f>;
			compatible = "ti,am335x-timer";
			ti,timer-pwm;
			ti,hwmods = "timer7";
			phandle = <0xb3>;
			linux,phandle = <0xb3>;
		};

		serial@44e09000 {
			reg = <0x44e09000 0x2000>;
			dmas = <0x2a 0x1a 0x0 0x2a 0x1b 0x0>;
			interrupts = <0x48>;
			pinctrl-0 = <0x2e>;
			compatible = "ti,am3352-uart", "ti,omap3-uart";
			clock-frequency = <0x2dc6c00>;
			status = "okay";
			ti,hwmods = "uart1";
			phandle = <0x91>;
			dma-names = "tx", "rx";
			pinctrl-names = "default";
			linux,phandle = <0x91>;
		};

		mmc@481d8000 {
			reg = <0x481d8000 0x1000>;
			dmas = <0x2a 0x2 0x0 0x2a 0x3 0x0>;
			interrupts = <0x1c>;
			vmmc-supply = <0x38>;
			pinctrl-0 = <0x39>;
			compatible = "ti,omap4-hsmmc";
			bus-width = <0x8>;
			status = "okay";
			ti,hwmods = "mmc2";
			phandle = <0xa7>;
			dma-names = "tx", "rx";
			pinctrl-names = "default";
			linux,phandle = <0xa7>;
			ti,needs-special-reset;
			interrupt-parent = <0x1>;
		};

		P8_15_pinmux {
			pinctrl-0 = <0x104>;
			pinctrl-1 = <0x105>;
			pinctrl-2 = <0x106>;
			pinctrl-3 = <0x107>;
			pinctrl-4 = <0x108>;
			pinctrl-5 = <0x109>;
			compatible = "bone-pinmux-helper";
			status = "okay";
			pinctrl-names = "default", "gpio", "gpio_pu", "gpio_pd", "pruin", "qep";
		};

		P8_10_pinmux {
			pinctrl-0 = <0xe9>;
			pinctrl-1 = <0xea>;
			pinctrl-2 = <0xeb>;
			pinctrl-3 = <0xec>;
			pinctrl-4 = <0xed>;
			compatible = "bone-pinmux-helper";
			status = "okay";
			pinctrl-names = "default", "gpio", "gpio_pu", "gpio_pd", "timer";
		};

		edma@49000000 {
			reg = <0x49000000 0x10000>;
			interrupts = <0xc 0xd 0xe>;
			dma-requests = <0x40>;
			reg-names = "edma3_cc";
			compatible = "ti,edma3-tpcc";
			interrupt-names = "edma3_ccint", "emda3_mperr", "edma3_ccerrint";
			ti,edma-memcpy-channels = <0x14 0x15>;
			#dma-cells = <0x2>;
			ti,hwmods = "tpcc";
			phandle = <0x2a>;
			linux,phandle = <0x2a>;
			ti,tptcs = <0x2b 0x7 0x2c 0x5 0x2d 0x0>;
		};

		rtc@44e3e000 {
			reg = <0x44e3e000 0x1000>;
			interrupts = <0x4b 0x4c>;
			compatible = "ti,am3352-rtc", "ti,da830-rtc";
			ti,hwmods = "rtc";
			phandle = <0xb4>;
			linux,phandle = <0xb4>;
			system-power-controller;
		};

		sgx@0x56000000 {
			reg = <0x56000000 0x1000000>;
			interrupts = <0x25>;
			compatible = "ti,am3352-sgx530", "img,sgx530";
			status = "okay";
			ti,hwmods = "gfx";
			phandle = <0xd6>;
			linux,phandle = <0xd6>;
		};

		timer@44e31000 {
			reg = <0x44e31000 0x400>;
			interrupts = <0x43>;
			compatible = "ti,am335x-timer-1ms";
			status = "disabled";
			ti,hwmods = "timer1";
			phandle = <0xad>;
			ti,timer-alwon;
			linux,phandle = <0xad>;
		};

		ethernet@4a100000 {
			reg = <0x4a100000 0x800 0x4a101200 0x100>;
			interrupts = <0x28 0x29 0x2a 0x2b>;
			pinctrl-0 = <0x43>;
			pinctrl-1 = <0x44>;
			compatible = "ti,am335x-cpsw", "ti,cpsw";
			clock-names = "fck", "cpts";
			no_bd_ram = <0x0>;
			mac_control = <0x20>;
			cpdma_channels = <0x8>;
			clocks = <0x41 0x42>;
			cpts_clock_shift = <0x1d>;
			ale_entries = <0x400>;
			cpts_clock_mult = <0x80000000>;
			ranges;
			rx_descs = <0x40>;
			slaves = <0x1>;
			status = "okay";
			syscon = <0x3b>;
			bd_ram_size = <0x2000>;
			#address-cells = <0x1>;
			active_slave = <0x0>;
			ti,hwmods = "cpgmac0";
			phandle = <0xc6>;
			#size-cells = <0x1>;
			pinctrl-names = "default", "sleep";
			linux,phandle = <0xc6>;
			interrupt-parent = <0x1>;

			cpsw-phy-sel@44e10650 {
				reg = <0x44e10650 0x4>;
				reg-names = "gmii-sel";
				compatible = "ti,am3352-cpsw-phy-sel";
				phandle = <0xc9>;
				linux,phandle = <0xc9>;
			};

			mdio@4a101000 {
				reg = <0x4a101000 0x100>;
				pinctrl-0 = <0x45>;
				pinctrl-1 = <0x46>;
				compatible = "ti,davinci_mdio";
				status = "okay";
				#address-cells = <0x1>;
				bus_freq = <0xf4240>;
				ti,hwmods = "davinci_mdio";
				phandle = <0x47>;
				#size-cells = <0x0>;
				pinctrl-names = "default", "sleep";
				linux,phandle = <0x47>;
			};

			slave@4a100200 {
				local-mac-address = [c4 f3 12 6f 48 c9];
				phy-mode = "mii";
				phy_id = <0x47 0x0>;
				mac-address = [c4 f3 12 6f 48 c9];
				phandle = <0xc7>;
				linux,phandle = <0xc7>;
			};

			slave@4a100300 {
				local-mac-address = [c4 f3 12 6f 48 cb];
				mac-address = [c4 f3 12 6f 48 cb];
				phandle = <0xc8>;
				linux,phandle = <0xc8>;
			};
		};

		tptc@49800000 {
			reg = <0x49800000 0x100000>;
			interrupts = <0x70>;
			compatible = "ti,edma3-tptc";
			interrupt-names = "edma3_tcerrint";
			ti,hwmods = "tptc0";
			phandle = <0x2b>;
			linux,phandle = <0x2b>;
		};

		P9_23_pinmux {
			pinctrl-0 = <0x15d>;
			pinctrl-1 = <0x15e>;
			pinctrl-2 = <0x15f>;
			pinctrl-3 = <0x160>;
			pinctrl-4 = <0x161>;
			compatible = "bone-pinmux-helper";
			status = "okay";
			pinctrl-names = "default", "gpio", "gpio_pu", "gpio_pd", "pwm";
		};

		tptc@49900000 {
			reg = <0x49900000 0x100000>;
			interrupts = <0x71>;
			compatible = "ti,edma3-tptc";
			interrupt-names = "edma3_tcerrint";
			ti,hwmods = "tptc1";
			phandle = <0x2c>;
			linux,phandle = <0x2c>;
		};

		gpmc@50000000 {
			reg = <0x50000000 0x2000>;
			dmas = <0x2a 0x34 0x0>;
			interrupts = <0x64>;
			#gpio-cells = <0x2>;
			compatible = "ti,am3352-gpmc";
			#interrupt-cells = <0x2>;
			status = "disabled";
			#address-cells = <0x2>;
			gpmc,num-cs = <0x7>;
			ti,no-idle-on-init;
			ti,hwmods = "gpmc";
			phandle = <0xd1>;
			interrupt-controller;
			#size-cells = <0x1>;
			gpmc,num-waitpins = <0x2>;
			gpio-controller;
			dma-names = "rxtx";
			linux,phandle = <0xd1>;
		};

		P9_14_pinmux {
			pinctrl-0 = <0x130>;
			pinctrl-1 = <0x131>;
			pinctrl-2 = <0x132>;
			pinctrl-3 = <0x133>;
			pinctrl-4 = <0x134>;
			compatible = "bone-pinmux-helper";
			status = "okay";
			pinctrl-names = "default", "gpio", "gpio_pu", "gpio_pd", "pwm";
		};

		P8_26_pinmux {
			pinctrl-0 = <0x11e>;
			pinctrl-1 = <0x11f>;
			pinctrl-2 = <0x120>;
			pinctrl-3 = <0x121>;
			compatible = "bone-pinmux-helper";
			status = "okay";
			pinctrl-names = "default", "gpio", "gpio_pu", "gpio_pd";
		};

		spinlock@480ca000 {
			reg = <0x480ca000 0x1000>;
			compatible = "ti,omap4-hwspinlock";
			#hwlock-cells = <0x1>;
			ti,hwmods = "spinlock";
			phandle = <0xa9>;
			linux,phandle = <0xa9>;
		};

		usb@47400000 {
			reg = <0x47400000 0x1000>;
			compatible = "ti,am33xx-usb";
			ranges;
			status = "okay";
			#address-cells = <0x1>;
			ti,hwmods = "usb_otg_hs";
			phandle = <0xb7>;
			#size-cells = <0x1>;
			linux,phandle = <0xb7>;

			control@44e10620 {
				reg = <0x44e10620 0x10 0x44e10648 0x4>;
				reg-names = "phy_ctrl", "wakeup";
				compatible = "ti,am335x-usb-ctrl-module";
				status = "okay";
				phandle = <0x3d>;
				linux,phandle = <0x3d>;
			};

			usb-phy@47401300 {
				reg = <0x47401300 0x100>;
				reg-names = "phy";
				compatible = "ti,am335x-usb-phy";
				ti,ctrl_mod = <0x3d>;
				status = "okay";
				phandle = <0x3e>;
				linux,phandle = <0x3e>;
			};

			usb-phy@47401b00 {
				reg = <0x47401b00 0x100>;
				reg-names = "phy";
				compatible = "ti,am335x-usb-phy";
				ti,ctrl_mod = <0x3d>;
				status = "okay";
				phandle = <0x40>;
				linux,phandle = <0x40>;
			};

			dma-controller@47402000 {
				reg = <0x47400000 0x1000 0x47402000 0x1000 0x47403000 0x1000 0x47404000 0x4000>;
				interrupts = <0x11>;
				reg-names = "glue", "controller", "scheduler", "queuemgr";
				compatible = "ti,am3359-cppi41";
				interrupt-names = "glue";
				#dma-requests = <0x100>;
				status = "okay";
				#dma-channels = <0x1e>;
				#dma-cells = <0x2>;
				phandle = <0x3f>;
				linux,phandle = <0x3f>;
			};

			usb@47401000 {
				reg = <0x47401400 0x400 0x47401000 0x200>;
				dmas = <0x3f 0x0 0x0 0x3f 0x1 0x0 0x3f 0x2 0x0 0x3f 0x3 0x0 0x3f 0x4 0x0 0x3f 0x5 0x0 0x3f 0x6 0x0 0x3f 0x7 0x0 0x3f 0x8 0x0 0x3f 0x9 0x0 0x3f 0xa 0x0 0x3f 0xb 0x0 0x3f 0xc 0x0 0x3f 0xd 0x0 0x3f 0xe 0x0 0x3f 0x0 0x1 0x3f 0x1 0x1 0x3f 0x2 0x1 0x3f 0x3 0x1 0x3f 0x4 0x1 0x3f 0x5 0x1 0x3f 0x6 0x1 0x3f 0x7 0x1 0x3f 0x8 0x1 0x3f 0x9 0x1 0x3f 0xa 0x1 0x3f 0xb 0x1 0x3f 0xc 0x1 0x3f 0xd 0x1 0x3f 0xe 0x1>;
				phys = <0x3e>;
				interrupts = <0x12>;
				reg-names = "mc", "control";
				compatible = "ti,musb-am33xx";
				mentor,multipoint = <0x1>;
				dr_mode = "peripheral";
				mentor,ram-bits = <0xc>;
				mentor,power = <0x1f4>;
				interrupt-names = "mc";
				mentor,num-eps = <0x10>;
				status = "okay";
				phandle = <0xb8>;
				dma-names = "rx1", "rx2", "rx3", "rx4", "rx5", "rx6", "rx7", "rx8", "rx9", "rx10", "rx11", "rx12", "rx13", "rx14", "rx15", "tx1", "tx2", "tx3", "tx4", "tx5", "tx6", "tx7", "tx8", "tx9", "tx10", "tx11", "tx12", "tx13", "tx14", "tx15";
				linux,phandle = <0xb8>;
			};

			usb@47401800 {
				reg = <0x47401c00 0x400 0x47401800 0x200>;
				dmas = <0x3f 0xf 0x0 0x3f 0x10 0x0 0x3f 0x11 0x0 0x3f 0x12 0x0 0x3f 0x13 0x0 0x3f 0x14 0x0 0x3f 0x15 0x0 0x3f 0x16 0x0 0x3f 0x17 0x0 0x3f 0x18 0x0 0x3f 0x19 0x0 0x3f 0x1a 0x0 0x3f 0x1b 0x0 0x3f 0x1c 0x0 0x3f 0x1d 0x0 0x3f 0xf 0x1 0x3f 0x10 0x1 0x3f 0x11 0x1 0x3f 0x12 0x1 0x3f 0x13 0x1 0x3f 0x14 0x1 0x3f 0x15 0x1 0x3f 0x16 0x1 0x3f 0x17 0x1 0x3f 0x18 0x1 0x3f 0x19 0x1 0x3f 0x1a 0x1 0x3f 0x1b 0x1 0x3f 0x1c 0x1 0x3f 0x1d 0x1>;
				phys = <0x40>;
				interrupts = <0x13>;
				reg-names = "mc", "control";
				compatible = "ti,musb-am33xx";
				mentor,multipoint = <0x1>;
				dr_mode = "host";
				mentor,ram-bits = <0xc>;
				mentor,power = <0x1f4>;
				interrupt-names = "mc";
				mentor,num-eps = <0x10>;
				status = "okay";
				phandle = <0xb9>;
				dma-names = "rx1", "rx2", "rx3", "rx4", "rx5", "rx6", "rx7", "rx8", "rx9", "rx10", "rx11", "rx12", "rx13", "rx14", "rx15", "tx1", "tx2", "tx3", "tx4", "tx5", "tx6", "tx7", "tx8", "tx9", "tx10", "tx11", "tx12", "tx13", "tx14", "tx15";
				linux,phandle = <0xb9>;
			};
		};

		P8_17_pinmux {
			pinctrl-0 = <0x110>;
			pinctrl-1 = <0x111>;
			pinctrl-2 = <0x112>;
			pinctrl-3 = <0x113>;
			pinctrl-4 = <0x114>;
			compatible = "bone-pinmux-helper";
			status = "okay";
			pinctrl-names = "default", "gpio", "gpio_pu", "gpio_pd", "pwm";
		};

		P8_12_pinmux {
			pinctrl-0 = <0xf4>;
			pinctrl-1 = <0xf5>;
			pinctrl-2 = <0xf6>;
			pinctrl-3 = <0xf7>;
			pinctrl-4 = <0xf8>;
			pinctrl-5 = <0xf9>;
			compatible = "bone-pinmux-helper";
			status = "okay";
			pinctrl-names = "default", "gpio", "gpio_pu", "gpio_pd", "pruout", "qep";
		};

		P8_08_pinmux {
			pinctrl-0 = <0xdf>;
			pinctrl-1 = <0xe0>;
			pinctrl-2 = <0xe1>;
			pinctrl-3 = <0xe2>;
			pinctrl-4 = <0xe3>;
			compatible = "bone-pinmux-helper";
			status = "okay";
			pinctrl-names = "default", "gpio", "gpio_pu", "gpio_pd", "timer";
		};
	};

	pmu {
		interrupts = <0x3>;
		compatible = "arm,cortex-a8-pmu";
	};

	soc {
		compatible = "ti,omap-infra";

		mpu {
			sram = <0x4>;
			compatible = "ti,omap3-mpu";
			ti,hwmods = "mpu";
		};
	};

	cpus {
		#address-cells = <0x1>;
		#size-cells = <0x0>;

		cpu@0 {
			reg = <0x0>;
			compatible = "arm,cortex-a8";
			clock-names = "cpu";
			voltage-tolerance = <0x2>;
			device_type = "cpu";
			clocks = <0x2>;
			clock-latency = <0x493e0>;
			cpu0-supply = <0x3>;
		};
	};

	leds {
		pinctrl-0 = <0x4d>;
		compatible = "gpio-leds";
		pinctrl-names = "default";

		led@2 {
			gpios = <0x4e 0x15 0x0>;
			label = "beaglebone:green:usr0";
			default-state = "off";
			linux,default-trigger = "heartbeat";
		};

		led@3 {
			gpios = <0x4e 0x16 0x0>;
			label = "beaglebone:green:usr1";
			default-state = "off";
			linux,default-trigger = "mmc0";
		};

		led@4 {
			gpios = <0x4e 0x17 0x0>;
			label = "beaglebone:green:usr2";
			default-state = "off";
			linux,default-trigger = "cpu0";
		};

		led@5 {
			gpios = <0x4e 0x18 0x0>;
			label = "beaglebone:green:usr3";
			default-state = "off";
			linux,default-trigger = "mmc1";
		};
	};

	fixedregulator@0 {
		regulator-name = "vmmcsd_fixed";
		compatible = "regulator-fixed";
		regulator-min-microvolt = <0x325aa0>;
		regulator-max-microvolt = <0x325aa0>;
		phandle = <0x38>;
		linux,phandle = <0x38>;
	};


	__local_fixups__ {
		interrupt-parent = <0x0>;

		ocp {

			i2c@4819c000 {
				pinctrl-0 = <0x0>;
			};

			lcdc@4830e000 {
				interrupt-parent = <0x0>;

				port {

					endpoint@0 {
						remote-endpoint = <0x0>;
					};
				};
			};

			i2c@44e0b000 {
				pinctrl-0 = <0x0>;

				tps@24 {
					interrupt-parent = <0x0>;
				};

				tda19988 {
					pinctrl-0 = <0x0>;
					pinctrl-1 = <0x0>;

					port {

						endpoint@0 {
							remote-endpoint = <0x0>;
						};
					};
				};
			};

			emif@4c000000 {
				sram = <0x0>;
			};

			l4_wkup@44c00000 {

				prcm@200000 {

					clockdomains {

						clk_24mhz_clkdm {
							clocks = <0x0>;
						};
					};

					clocks {

						clkdiv32k_ick {
							clocks = <0x0>;
						};

						clkout2_div_ck {
							clocks = <0x0>;
						};

						gpio0_dbclk {
							clocks = <0x0>;
						};

						pruss_ocp_gclk {
							clocks = <0x0 0x4>;
						};

						dbg_clka_ck {
							clocks = <0x0>;
						};

						gfx_fclk_clksel_ck {
							clocks = <0x0 0x4>;
						};

						l4hs_gclk {
							clocks = <0x0>;
						};

						dpll_per_m2_ck {
							clocks = <0x0>;
						};

						l3s_gclk {
							clocks = <0x0>;
						};

						gpio1_dbclk {
							clocks = <0x0>;
						};

						dpll_core_ck {
							clocks = <0x0 0x4>;
						};

						trace_pmd_clk_mux_ck {
							clocks = <0x0 0x4>;
						};

						dpll_disp_ck {
							clocks = <0x0 0x4>;
						};

						stm_clk_div_ck {
							clocks = <0x0>;
						};

						cefuse_fck {
							clocks = <0x0>;
						};

						cpsw_125mhz_gclk {
							clocks = <0x0>;
						};

						gpio2_dbclk {
							clocks = <0x0>;
						};

						dpll_core_m4_ck {
							clocks = <0x0>;
						};

						dpll_core_m5_ck {
							clocks = <0x0>;
						};

						dpll_core_m6_ck {
							clocks = <0x0>;
						};

						dpll_core_x2_ck {
							clocks = <0x0>;
						};

						dbg_sysclk_ck {
							clocks = <0x0>;
						};

						clkout2_ck {
							clocks = <0x0>;
						};

						dpll_disp_m2_ck {
							clocks = <0x0>;
						};

						dpll_mpu_m2_ck {
							clocks = <0x0>;
						};

						sysclk_div_ck {
							clocks = <0x0>;
						};

						mmc_clk {
							clocks = <0x0>;
						};

						clkdiv32k_ck {
							clocks = <0x0>;
						};

						ieee5000_fck {
							clocks = <0x0>;
						};

						cpsw_cpts_rft_clk {
							clocks = <0x0 0x4>;
						};

						mmu_fck {
							clocks = <0x0>;
						};

						gpio3_dbclk {
							clocks = <0x0>;
						};

						stm_pmd_clock_mux_ck {
							clocks = <0x0 0x4>;
						};

						gfx_fck_div_ck {
							clocks = <0x0>;
						};

						l3_gclk {
							clocks = <0x0>;
						};

						l4_rtc_gclk {
							clocks = <0x0>;
						};

						dpll_per_m2_div4_wkupdm_ck {
							clocks = <0x0>;
						};

						dpll_ddr_m2_ck {
							clocks = <0x0>;
						};

						sysclkout_pre_ck {
							clocks = <0x0 0x4 0x8 0xc 0x10>;
						};

						dpll_per_m2_div4_ck {
							clocks = <0x0>;
						};

						timer1_fck {
							clocks = <0x0 0x4 0x8 0xc 0x10>;
						};

						timer2_fck {
							clocks = <0x0 0x4 0x8>;
						};

						timer3_fck {
							clocks = <0x0 0x4 0x8>;
						};

						usbotg_fck {
							clocks = <0x0>;
						};

						timer4_fck {
							clocks = <0x0 0x4 0x8>;
						};

						timer5_fck {
							clocks = <0x0 0x4 0x8>;
						};

						timer6_fck {
							clocks = <0x0 0x4 0x8>;
						};

						timer7_fck {
							clocks = <0x0 0x4 0x8>;
						};

						dpll_ddr_ck {
							clocks = <0x0 0x4>;
						};

						gpio0_dbclk_mux_ck {
							clocks = <0x0 0x4 0x8>;
						};

						l4ls_gclk {
							clocks = <0x0>;
						};

						dpll_ddr_m2_div2_ck {
							clocks = <0x0>;
						};

						trace_clk_div_ck {
							clocks = <0x0>;
						};

						dpll_mpu_ck {
							clocks = <0x0 0x4>;
						};

						dpll_per_ck {
							clocks = <0x0 0x4>;
						};

						clk_24mhz {
							clocks = <0x0>;
						};

						dpll_core_m4_div2_ck {
							clocks = <0x0>;
						};

						l4fw_gclk {
							clocks = <0x0>;
						};

						wdt1_fck {
							clocks = <0x0 0x4>;
						};

						lcd_gclk {
							clocks = <0x0 0x4 0x8>;
						};
					};
				};

				scm@210000 {

					pinmux@800 {
						pinctrl-0 = <0x0>;
					};

					wkup_m3_ipc@1324 {
						mboxes = <0x0 0x4>;
						ti,rproc = <0x0>;
					};

					dma-router@f90 {
						dma-masters = <0x0>;
					};

					scm_conf@0 {

						clocks {

							sys_clkin_ck {
								clocks = <0x0 0x4 0x8 0xc>;
							};

							rng_fck {
								clocks = <0x0>;
							};

							ehrpwm2_tbclk@44e10664 {
								clocks = <0x0>;
							};

							mcasp0_fck {
								clocks = <0x0>;
							};

							mcasp1_fck {
								clocks = <0x0>;
							};

							ehrpwm1_tbclk@44e10664 {
								clocks = <0x0>;
							};

							adc_tsc_fck {
								clocks = <0x0>;
							};

							smartreflex0_fck {
								clocks = <0x0>;
							};

							smartreflex1_fck {
								clocks = <0x0>;
							};

							ehrpwm0_tbclk@44e10664 {
								clocks = <0x0>;
							};

							dcan0_fck {
								clocks = <0x0>;
							};

							dcan1_fck {
								clocks = <0x0>;
							};

							aes0_fck {
								clocks = <0x0>;
							};

							sha0_fck {
								clocks = <0x0>;
							};
						};
					};
				};
			};

			epwmss@48300000 {

				eqep@0x48300180 {
					interrupt-parent = <0x0>;
				};
			};

			epwmss@48302000 {

				eqep@0x48302180 {
					interrupt-parent = <0x0>;
				};
			};

			epwmss@48304000 {

				eqep@0x48304180 {
					interrupt-parent = <0x0>;
				};
			};

			spi@48030000 {
				dmas = <0x0 0xc 0x18 0x24>;
			};

			aes@53500000 {
				dmas = <0x0 0xc>;
			};

			spi@481a0000 {
				dmas = <0x0 0xc 0x18 0x24>;
			};

			can@481d0000 {
				clocks = <0x0>;
				syscon-raminit = <0x0>;
			};

			can@481cc000 {
				clocks = <0x0>;
				syscon-raminit = <0x0>;
			};

			sham@53100000 {
				dmas = <0x0>;
			};

			tscadc@44e0d000 {
				interrupt-parent = <0x0>;
			};

			mcasp@48038000 {
				dmas = <0x0 0xc>;
				pinctrl-0 = <0x0>;
				pinctrl-1 = <0x0>;
			};

			mcasp@4803C000 {
				dmas = <0x0 0xc>;
			};

			serial@48022000 {
				dmas = <0x0 0xc>;
			};

			serial@48024000 {
				dmas = <0x0 0xc>;
			};

			mmc@47810000 {
				interrupt-parent = <0x0>;
			};

			mmc@48060000 {
				dmas = <0x0 0x10>;
				cd-gpios = <0x0>;
				vmmc-supply = <0x0>;
				pinctrl-0 = <0x0>;
				pinctrl-1 = <0x0>;
				interrupt-parent = <0x0>;
			};

			pruss@4a300000 {

				pru@4a334000 {
					mboxes = <0x0 0x4>;
				};

				pru@4a338000 {
					mboxes = <0x0 0x4>;
				};
			};

			serial@44e09000 {
				dmas = <0x0 0xc>;
				pinctrl-0 = <0x0>;
			};

			mmc@481d8000 {
				dmas = <0x0 0xc>;
				vmmc-supply = <0x0>;
				pinctrl-0 = <0x0>;
				interrupt-parent = <0x0>;
			};

			edma@49000000 {
				ti,tptcs = <0x0 0x8 0x10>;
			};

			ethernet@4a100000 {
				pinctrl-0 = <0x0>;
				pinctrl-1 = <0x0>;
				clocks = <0x0 0x4>;
				syscon = <0x0>;
				interrupt-parent = <0x0>;

				mdio@4a101000 {
					pinctrl-0 = <0x0>;
					pinctrl-1 = <0x0>;
				};

				slave@4a100200 {
					phy_id = <0x0>;
				};
			};

			gpmc@50000000 {
				dmas = <0x0>;
			};

			usb@47400000 {

				usb-phy@47401300 {
					ti,ctrl_mod = <0x0>;
				};

				usb-phy@47401b00 {
					ti,ctrl_mod = <0x0>;
				};

				usb@47401000 {
					dmas = <0x0 0xc 0x18 0x24 0x30 0x3c 0x48 0x54 0x60 0x6c 0x78 0x84 0x90 0x9c 0xa8 0xb4 0xc0 0xcc 0xd8 0xe4 0xf0 0xfc 0x108 0x114 0x120 0x12c 0x138 0x144 0x150 0x15c>;
					phys = <0x0>;
				};

				usb@47401800 {
					dmas = <0x0 0xc 0x18 0x24 0x30 0x3c 0x48 0x54 0x60 0x6c 0x78 0x84 0x90 0x9c 0xa8 0xb4 0xc0 0xcc 0xd8 0xe4 0xf0 0xfc 0x108 0x114 0x120 0x12c 0x138 0x144 0x150 0x15c>;
					phys = <0x0>;
				};
			};
		};

		soc {

			mpu {
				sram = <0x0>;
			};
		};

		cpus {

			cpu@0 {
				clocks = <0x0>;
				cpu0-supply = <0x0>;
			};
		};

		leds {
			pinctrl-0 = <0x0>;

			led@2 {
				gpios = <0x0>;
			};

			led@3 {
				gpios = <0x0>;
			};

			led@4 {
				gpios = <0x0>;
			};

			led@5 {
				gpios = <0x0>;
			};
		};

		clk_mcasp0 {
			clocks = <0x0>;
			enable-gpios = <0x0>;
		};
	};

	chosen {
		linux,initrd-end = <0x8ffff0f1>;
		bootargs = "console=ttyO0,115200n8 root=UUID=3e612fba-d7aa-4f53-a46c-21248b841756 ro rootfstype=ext4 rootwait coherent_pool=1M quiet cape_universal=enable";
		linux,initrd-start = <0x8fc17000>;
	};

	memory {
		reg = <0x80000000 0x20000000>;
		device_type = "memory";
	};

	__symbols__ {
		aes = "/ocp/aes@53500000";
		elm = "/ocp/elm@48080000";
		mac = "/ocp/ethernet@4a100000";
		ocp = "/ocp";
		rng = "/ocp/rng@48310000";
		scm = "/ocp/l4_wkup@44c00000/scm@210000";
		sgx = "/ocp/sgx@0x56000000";
		rtc = "/ocp/rtc@44e3e000";
		tps = "/ocp/i2c@44e0b000/tps@24";
		usb = "/ocp/usb@47400000";
		clkdiv32k_ick = "/ocp/l4_wkup@44c00000/prcm@200000/clocks/clkdiv32k_ick";
		i2c0 = "/ocp/i2c@44e0b000";
		i2c1 = "/ocp/i2c@4802a000";
		i2c2 = "/ocp/i2c@4819c000";
		edma = "/ocp/edma@49000000";
		emif = "/ocp/emif@4c000000";
		gpmc = "/ocp/gpmc@50000000";
		intc = "/ocp/interrupt-controller@48200000";
		lcdc = "/ocp/lcdc@4830e000";
		mmc1 = "/ocp/mmc@48060000";
		mmc2 = "/ocp/mmc@481d8000";
		mmc3 = "/ocp/mmc@47810000";
		prcm = "/ocp/l4_wkup@44c00000/prcm@200000";
		pru0 = "/ocp/pruss@4a300000/pru@4a334000";
		pru1 = "/ocp/pruss@4a300000/pru@4a338000";
		sham = "/ocp/sham@53100000";
		spi0 = "/ocp/spi@48030000";
		spi1 = "/ocp/spi@481a0000";
		usb0 = "/ocp/usb@47400000/usb@47401000";
		usb1 = "/ocp/usb@47400000/usb@47401800";
		wdt2 = "/ocp/wdt@44e35000";
		clkout2_div_ck = "/ocp/l4_wkup@44c00000/prcm@200000/clocks/clkout2_div_ck";
		ehrpwm1_tbclk = "/ocp/l4_wkup@44c00000/scm@210000/scm_conf@0/clocks/ehrpwm1_tbclk@44e10664";
		gpio0_dbclk = "/ocp/l4_wkup@44c00000/prcm@200000/clocks/gpio0_dbclk";
		sys_clkin_ck = "/ocp/l4_wkup@44c00000/scm@210000/scm_conf@0/clocks/sys_clkin_ck";
		dcdc1_reg = "/ocp/i2c@44e0b000/tps@24/regulators/regulator@0";
		dcdc2_reg = "/ocp/i2c@44e0b000/tps@24/regulators/regulator@1";
		dcdc3_reg = "/ocp/i2c@44e0b000/tps@24/regulators/regulator@2";
		pruss_ocp_gclk = "/ocp/l4_wkup@44c00000/prcm@200000/clocks/pruss_ocp_gclk";
		dbg_clka_ck = "/ocp/l4_wkup@44c00000/prcm@200000/clocks/dbg_clka_ck";
		gfx_fclk_clksel_ck = "/ocp/l4_wkup@44c00000/prcm@200000/clocks/gfx_fclk_clksel_ck";
		l4hs_gclk = "/ocp/l4_wkup@44c00000/prcm@200000/clocks/l4hs_gclk";
		davinci_mdio = "/ocp/ethernet@4a100000/mdio@4a101000";
		dpll_per_m2_ck = "/ocp/l4_wkup@44c00000/prcm@200000/clocks/dpll_per_m2_ck";
		clk_32768_ck = "/ocp/l4_wkup@44c00000/prcm@200000/clocks/clk_32768_ck";
		hdmi_audio = "/hdmi_audio@0";
		virt_24000000_ck = "/ocp/l4_wkup@44c00000/prcm@200000/clocks/virt_24000000_ck";
		baseboard_eeprom = "/ocp/i2c@44e0b000/baseboard_eeprom@50";
		dcan0 = "/ocp/can@481cc000";
		dcan1 = "/ocp/can@481d0000";
		ecap0 = "/ocp/epwmss@48300000/ecap@48300100";
		ecap1 = "/ocp/epwmss@48302000/ecap@48302100";
		ecap2 = "/ocp/epwmss@48304000/ecap@48304100";
		eqep0 = "/ocp/epwmss@48300000/eqep@0x48300180";
		eqep1 = "/ocp/epwmss@48302000/eqep@0x48302180";
		eqep2 = "/ocp/epwmss@48304000/eqep@0x48304180";
		gpio0 = "/ocp/gpio@44e07000";
		gpio1 = "/ocp/gpio@4804c000";
		gpio2 = "/ocp/gpio@481ac000";
		gpio3 = "/ocp/gpio@481ae000";
		pruss = "/ocp/pruss@4a300000";
		uart0 = "/ocp/serial@44e09000";
		uart1 = "/ocp/serial@48022000";
		uart2 = "/ocp/serial@48024000";
		uart3 = "/ocp/serial@481a6000";
		uart4 = "/ocp/serial@481a8000";
		uart5 = "/ocp/serial@481aa000";
		am335x_adc = "/ocp/tscadc@44e0d000/adc";
		l3s_gclk = "/ocp/l4_wkup@44c00000/prcm@200000/clocks/l3s_gclk";
		ehrpwm2_tbclk = "/ocp/l4_wkup@44c00000/scm@210000/scm_conf@0/clocks/ehrpwm2_tbclk@44e10664";
		cppi41dma = "/ocp/usb@47400000/dma-controller@47402000";
		gpio1_dbclk = "/ocp/l4_wkup@44c00000/prcm@200000/clocks/gpio1_dbclk";
		ldo1_reg = "/ocp/i2c@44e0b000/tps@24/regulators/regulator@3";
		ldo2_reg = "/ocp/i2c@44e0b000/tps@24/regulators/regulator@4";
		ldo3_reg = "/ocp/i2c@44e0b000/tps@24/regulators/regulator@5";
		ldo4_reg = "/ocp/i2c@44e0b000/tps@24/regulators/regulator@6";
		dpll_core_ck = "/ocp/l4_wkup@44c00000/prcm@200000/clocks/dpll_core_ck";
		rng_fck = "/ocp/l4_wkup@44c00000/scm@210000/scm_conf@0/clocks/rng_fck";
		clk_rc32k_ck = "/ocp/l4_wkup@44c00000/prcm@200000/clocks/clk_rc32k_ck";
		edma_tptc0 = "/ocp/tptc@49800000";
		edma_tptc1 = "/ocp/tptc@49900000";
		edma_tptc2 = "/ocp/tptc@49a00000";
		ehrpwm0 = "/ocp/epwmss@48300000/ehrpwm@48300200";
		ehrpwm1 = "/ocp/epwmss@48302000/ehrpwm@48302200";
		ehrpwm2 = "/ocp/epwmss@48304000/ehrpwm@48304200";
		trace_pmd_clk_mux_ck = "/ocp/l4_wkup@44c00000/prcm@200000/clocks/trace_pmd_clk_mux_ck";
		mcasp0_fck = "/ocp/l4_wkup@44c00000/scm@210000/scm_conf@0/clocks/mcasp0_fck";
		mcasp1_fck = "/ocp/l4_wkup@44c00000/scm@210000/scm_conf@0/clocks/mcasp1_fck";
		cpsw_default = "/ocp/l4_wkup@44c00000/scm@210000/pinmux@800/cpsw_default";
		dpll_disp_ck = "/ocp/l4_wkup@44c00000/prcm@200000/clocks/dpll_disp_ck";
		stm_clk_div_ck = "/ocp/l4_wkup@44c00000/prcm@200000/clocks/stm_clk_div_ck";
		clk_24mhz_clkdm = "/ocp/l4_wkup@44c00000/prcm@200000/clockdomains/clk_24mhz_clkdm";
		cefuse_fck = "/ocp/l4_wkup@44c00000/prcm@200000/clocks/cefuse_fck";
		cpsw_125mhz_gclk = "/ocp/l4_wkup@44c00000/prcm@200000/clocks/cpsw_125mhz_gclk";
		mailbox = "/ocp/mailbox@480C8000";
		gpio2_dbclk = "/ocp/l4_wkup@44c00000/prcm@200000/clocks/gpio2_dbclk";
		prcm_clocks = "/ocp/l4_wkup@44c00000/prcm@200000/clocks";
		am33xx_pinmux = "/ocp/l4_wkup@44c00000/scm@210000/pinmux@800";
		nxp_hdmi_bonelt_off_pins = "/ocp/l4_wkup@44c00000/scm@210000/pinmux@800/nxp_hdmi_bonelt_off_pins";
		epwmss0 = "/ocp/epwmss@48300000";
		epwmss1 = "/ocp/epwmss@48302000";
		epwmss2 = "/ocp/epwmss@48304000";
		scm_conf = "/ocp/l4_wkup@44c00000/scm@210000/scm_conf@0";
		dpll_core_m4_ck = "/ocp/l4_wkup@44c00000/prcm@200000/clocks/dpll_core_m4_ck";
		dpll_core_m5_ck = "/ocp/l4_wkup@44c00000/prcm@200000/clocks/dpll_core_m5_ck";
		dpll_core_m6_ck = "/ocp/l4_wkup@44c00000/prcm@200000/clocks/dpll_core_m6_ck";
		virt_25000000_ck = "/ocp/l4_wkup@44c00000/prcm@200000/clocks/virt_25000000_ck";
		dpll_core_x2_ck = "/ocp/l4_wkup@44c00000/prcm@200000/clocks/dpll_core_x2_ck";
		dbg_sysclk_ck = "/ocp/l4_wkup@44c00000/prcm@200000/clocks/dbg_sysclk_ck";
		clkout2_ck = "/ocp/l4_wkup@44c00000/prcm@200000/clocks/clkout2_ck";
		dpll_disp_m2_ck = "/ocp/l4_wkup@44c00000/prcm@200000/clocks/dpll_disp_m2_ck";
		dpll_mpu_m2_ck = "/ocp/l4_wkup@44c00000/prcm@200000/clocks/dpll_mpu_m2_ck";
		cape_eeprom0 = "/ocp/i2c@4819c000/cape_eeprom0@54";
		cape_eeprom1 = "/ocp/i2c@4819c000/cape_eeprom1@55";
		cape_eeprom2 = "/ocp/i2c@4819c000/cape_eeprom2@56";
		cape_eeprom3 = "/ocp/i2c@4819c000/cape_eeprom3@57";
		sysclk_div_ck = "/ocp/l4_wkup@44c00000/prcm@200000/clocks/sysclk_div_ck";
		clkout2_pin = "/ocp/l4_wkup@44c00000/scm@210000/pinmux@800/pinmux_clkout2_pin";
		nxp_hdmi_bonelt_pins = "/ocp/l4_wkup@44c00000/scm@210000/pinmux@800/nxp_hdmi_bonelt_pins";
		mmc_clk = "/ocp/l4_wkup@44c00000/prcm@200000/clocks/mmc_clk";
		clkdiv32k_ck = "/ocp/l4_wkup@44c00000/prcm@200000/clocks/clkdiv32k_ck";
		prcm_clockdomains = "/ocp/l4_wkup@44c00000/prcm@200000/clockdomains";
		ieee5000_fck = "/ocp/l4_wkup@44c00000/prcm@200000/clocks/ieee5000_fck";
		cpsw_cpts_rft_clk = "/ocp/l4_wkup@44c00000/prcm@200000/clocks/cpsw_cpts_rft_clk";
		mmu_fck = "/ocp/l4_wkup@44c00000/prcm@200000/clocks/mmu_fck";
		gpio3_dbclk = "/ocp/l4_wkup@44c00000/prcm@200000/clocks/gpio3_dbclk";
		hdmi_0 = "/ocp/i2c@44e0b000/tda19988/port/endpoint@0";
		mbox_pru0 = "/ocp/mailbox@480C8000/mbox_pru0";
		mbox_pru1 = "/ocp/mailbox@480C8000/mbox_pru1";
		cpsw_emac0 = "/ocp/ethernet@4a100000/slave@4a100200";
		cpsw_emac1 = "/ocp/ethernet@4a100000/slave@4a100300";
		stm_pmd_clock_mux_ck = "/ocp/l4_wkup@44c00000/prcm@200000/clocks/stm_pmd_clock_mux_ck";
		gfx_fck_div_ck = "/ocp/l4_wkup@44c00000/prcm@200000/clocks/gfx_fck_div_ck";
		cpsw_sleep = "/ocp/l4_wkup@44c00000/scm@210000/pinmux@800/cpsw_sleep";
		l3_gclk = "/ocp/l4_wkup@44c00000/prcm@200000/clocks/l3_gclk";
		l4_wkup = "/ocp/l4_wkup@44c00000";
		l4_rtc_gclk = "/ocp/l4_wkup@44c00000/prcm@200000/clocks/l4_rtc_gclk";
		lcdc_0 = "/ocp/lcdc@4830e000/port/endpoint@0";
		dpll_per_m2_div4_wkupdm_ck = "/ocp/l4_wkup@44c00000/prcm@200000/clocks/dpll_per_m2_div4_wkupdm_ck";
		edma_xbar = "/ocp/l4_wkup@44c00000/scm@210000/dma-router@f90";
		mcasp0 = "/ocp/mcasp@48038000";
		mcasp1 = "/ocp/mcasp@4803C000";
		i2c0_pins = "/ocp/l4_wkup@44c00000/scm@210000/pinmux@800/pinmux_i2c0_pins";
		tclkin_ck = "/ocp/l4_wkup@44c00000/prcm@200000/clocks/tclkin_ck";
		dpll_ddr_m2_ck = "/ocp/l4_wkup@44c00000/prcm@200000/clocks/dpll_ddr_m2_ck";
		sysclkout_pre_ck = "/ocp/l4_wkup@44c00000/prcm@200000/clocks/sysclkout_pre_ck";
		i2c2_pins = "/ocp/l4_wkup@44c00000/scm@210000/pinmux@800/pinmux_i2c2_pins";
		virt_26000000_ck = "/ocp/l4_wkup@44c00000/prcm@200000/clocks/virt_26000000_ck";
		ocmcram = "/ocp/ocmcram@40300000";
		dpll_per_m2_div4_ck = "/ocp/l4_wkup@44c00000/prcm@200000/clocks/dpll_per_m2_div4_ck";
		timer1_fck = "/ocp/l4_wkup@44c00000/prcm@200000/clocks/timer1_fck";
		timer2_fck = "/ocp/l4_wkup@44c00000/prcm@200000/clocks/timer2_fck";
		timer3_fck = "/ocp/l4_wkup@44c00000/prcm@200000/clocks/timer3_fck";
		usbotg_fck = "/ocp/l4_wkup@44c00000/prcm@200000/clocks/usbotg_fck";
		timer4_fck = "/ocp/l4_wkup@44c00000/prcm@200000/clocks/timer4_fck";
		timer5_fck = "/ocp/l4_wkup@44c00000/prcm@200000/clocks/timer5_fck";
		timer6_fck = "/ocp/l4_wkup@44c00000/prcm@200000/clocks/timer6_fck";
		timer7_fck = "/ocp/l4_wkup@44c00000/prcm@200000/clocks/timer7_fck";
		davinci_mdio_default = "/ocp/l4_wkup@44c00000/scm@210000/pinmux@800/davinci_mdio_default";
		dpll_ddr_ck = "/ocp/l4_wkup@44c00000/prcm@200000/clocks/dpll_ddr_ck";
		adc_tsc_fck = "/ocp/l4_wkup@44c00000/scm@210000/scm_conf@0/clocks/adc_tsc_fck";
		gpio0_dbclk_mux_ck = "/ocp/l4_wkup@44c00000/prcm@200000/clocks/gpio0_dbclk_mux_ck";
		l4ls_gclk = "/ocp/l4_wkup@44c00000/prcm@200000/clocks/l4ls_gclk";
		timer1 = "/ocp/timer@44e31000";
		timer2 = "/ocp/timer@48040000";
		timer3 = "/ocp/timer@48042000";
		timer4 = "/ocp/timer@48044000";
		timer5 = "/ocp/timer@48046000";
		timer6 = "/ocp/timer@48048000";
		timer7 = "/ocp/timer@4804a000";
		dpll_ddr_m2_div2_ck = "/ocp/l4_wkup@44c00000/prcm@200000/clocks/dpll_ddr_m2_div2_ck";
		tscadc = "/ocp/tscadc@44e0d000";
		usb0_phy = "/ocp/usb@47400000/usb-phy@47401300";
		usb1_phy = "/ocp/usb@47400000/usb-phy@47401b00";
		smartreflex0_fck = "/ocp/l4_wkup@44c00000/scm@210000/scm_conf@0/clocks/smartreflex0_fck";
		smartreflex1_fck = "/ocp/l4_wkup@44c00000/scm@210000/scm_conf@0/clocks/smartreflex1_fck";
		user_leds_s0 = "/ocp/l4_wkup@44c00000/scm@210000/pinmux@800/user_leds_s0";
		davinci_mdio_sleep = "/ocp/l4_wkup@44c00000/scm@210000/pinmux@800/davinci_mdio_sleep";
		trace_clk_div_ck = "/ocp/l4_wkup@44c00000/prcm@200000/clocks/trace_clk_div_ck";
		mcasp0_pins_sleep = "/ocp/l4_wkup@44c00000/scm@210000/pinmux@800/mcasp0_pins_sleep";
		virt_19200000_ck = "/ocp/l4_wkup@44c00000/prcm@200000/clocks/virt_19200000_ck";
		dcan0_fck = "/ocp/l4_wkup@44c00000/scm@210000/scm_conf@0/clocks/dcan0_fck";
		dcan1_fck = "/ocp/l4_wkup@44c00000/scm@210000/scm_conf@0/clocks/dcan1_fck";
		mmc1_pins_default = "/ocp/l4_wkup@44c00000/scm@210000/pinmux@800/pinmux_mmc1_pins";
		dpll_mpu_ck = "/ocp/l4_wkup@44c00000/prcm@200000/clocks/dpll_mpu_ck";
		uart0_pins = "/ocp/l4_wkup@44c00000/scm@210000/pinmux@800/pinmux_uart0_pins";
		mcasp0_pins = "/ocp/l4_wkup@44c00000/scm@210000/pinmux@800/mcasp0_pins";
		dpll_per_ck = "/ocp/l4_wkup@44c00000/prcm@200000/clocks/dpll_per_ck";
		usb_ctrl_mod = "/ocp/usb@47400000/control@44e10620";
		vmmcsd_fixed = "/fixedregulator@0";
		clk_24mhz = "/ocp/l4_wkup@44c00000/prcm@200000/clocks/clk_24mhz";
		clk_mcasp0_fixed = "/clk_mcasp0_fixed";
		aes0_fck = "/ocp/l4_wkup@44c00000/scm@210000/scm_conf@0/clocks/aes0_fck";
		scm_clockdomains = "/ocp/l4_wkup@44c00000/scm@210000/clockdomains";
		dpll_core_m4_div2_ck = "/ocp/l4_wkup@44c00000/prcm@200000/clocks/dpll_core_m4_div2_ck";
		cape0_data = "/ocp/i2c@4819c000/cape_eeprom0@54/cape_data@0";
		l4fw_gclk = "/ocp/l4_wkup@44c00000/prcm@200000/clocks/l4fw_gclk";
		phy_sel = "/ocp/ethernet@4a100000/cpsw-phy-sel@44e10650";
		hwspinlock = "/ocp/spinlock@480ca000";
		cape1_data = "/ocp/i2c@4819c000/cape_eeprom1@55/cape_data@0";
		sha0_fck = "/ocp/l4_wkup@44c00000/scm@210000/scm_conf@0/clocks/sha0_fck";
		cape2_data = "/ocp/i2c@4819c000/cape_eeprom2@56/cape_data@0";
		ehrpwm0_tbclk = "/ocp/l4_wkup@44c00000/scm@210000/scm_conf@0/clocks/ehrpwm0_tbclk@44e10664";
		cape3_data = "/ocp/i2c@4819c000/cape_eeprom3@57/cape_data@0";
		baseboard_data = "/ocp/i2c@44e0b000/baseboard_eeprom@50/baseboard_data@0";
		wkup_m3 = "/ocp/l4_wkup@44c00000/wkup_m3@100000";
		wdt1_fck = "/ocp/l4_wkup@44c00000/prcm@200000/clocks/wdt1_fck";
		clk_mcasp0 = "/clk_mcasp0";
		mbox_wkupm3 = "/ocp/mailbox@480C8000/wkup_m3";
		wkup_m3_ipc = "/ocp/l4_wkup@44c00000/scm@210000/wkup_m3_ipc@1324";
		lcd_gclk = "/ocp/l4_wkup@44c00000/prcm@200000/clocks/lcd_gclk";
		emmc_pins = "/ocp/l4_wkup@44c00000/scm@210000/pinmux@800/pinmux_emmc_pins";
		scm_clocks = "/ocp/l4_wkup@44c00000/scm@210000/scm_conf@0/clocks";
		mmc1_pins_sleep = "/ocp/l4_wkup@44c00000/scm@210000/pinmux@800/pinmux_mmc1_pins_sleep";
	};

	aliases {
		i2c0 = "/ocp/i2c@44e0b000";
		i2c1 = "/ocp/i2c@4802a000";
		i2c2 = "/ocp/i2c@4819c000";
		phy0 = "/ocp/usb@47400000/usb-phy@47401300";
		phy1 = "/ocp/usb@47400000/usb-phy@47401b00";
		usb0 = "/ocp/usb@47400000/usb@47401000";
		usb1 = "/ocp/usb@47400000/usb@47401800";
		serial0 = "/ocp/serial@44e09000";
		serial1 = "/ocp/serial@48022000";
		serial2 = "/ocp/serial@48024000";
		serial3 = "/ocp/serial@481a6000";
		serial4 = "/ocp/serial@481a8000";
		serial5 = "/ocp/serial@481aa000";
		d_can0 = "/ocp/can@481cc000";
		d_can1 = "/ocp/can@481d0000";
		ethernet0 = "/ocp/ethernet@4a100000/slave@4a100200";
		ethernet1 = "/ocp/ethernet@4a100000/slave@4a100300";
	};

	clk_mcasp0_fixed {
		#clock-cells = <0x0>;
		compatible = "fixed-clock";
		clock-frequency = <0x1770000>;
		phandle = <0x54>;
		linux,phandle = <0x54>;
	};

	clk_mcasp0 {
		#clock-cells = <0x0>;
		compatible = "gpio-gate-clock";
		clocks = <0x54>;
		enable-gpios = <0x4e 0x1b 0x0>;
		phandle = <0x57>;
		linux,phandle = <0x57>;
	};
};
